[part 1 of 3: packages /AUTOSAR_Dem/ImplementationDataTypes to /AUTOSAR_Dem/SwComponentTypes]
AUTOSAR XML (schema 4-0-3)
package /AUTOSAR_Dem/ImplementationDataTypes
  4 x impl type, all with category=TYPE_REFERENCE, implementation-data-type=uint8:
    Dem_OperationCycleIdType: compu {0=DEM_OPCYC_POWER, 1=DEM_OPCYC_IGN}, range raw 0..1
    Dem_IndicatorIdType: range raw 0
    Dem_RatioIdType: range raw 0
    Dem_EnableConditionType: compu {0=DemConf_DemEnableCondition_CONDITION_Voltage_Normal, 1=DemConf_DemEnableCondition_CONDITION_PowerON_3000ms, 2=DemConf_DemEnableCondition_CONDITION_Voltage_InRange, 3=DemConf_DemEnableCondition_CONDITION_NO_BUSOFF_PublicCAN, 4=DemConf_DemEnableCondition_CONDITION_NO_BUSOFF_PrivateCAN, 5=DemConf_DemEnableCondition_CONDITION_BcmPwrStsFbON, 6=DemConf_DemEnableCondition_CONDITION_EspVehSpd}
package /AUTOSAR_Dem/SwComponentTypes
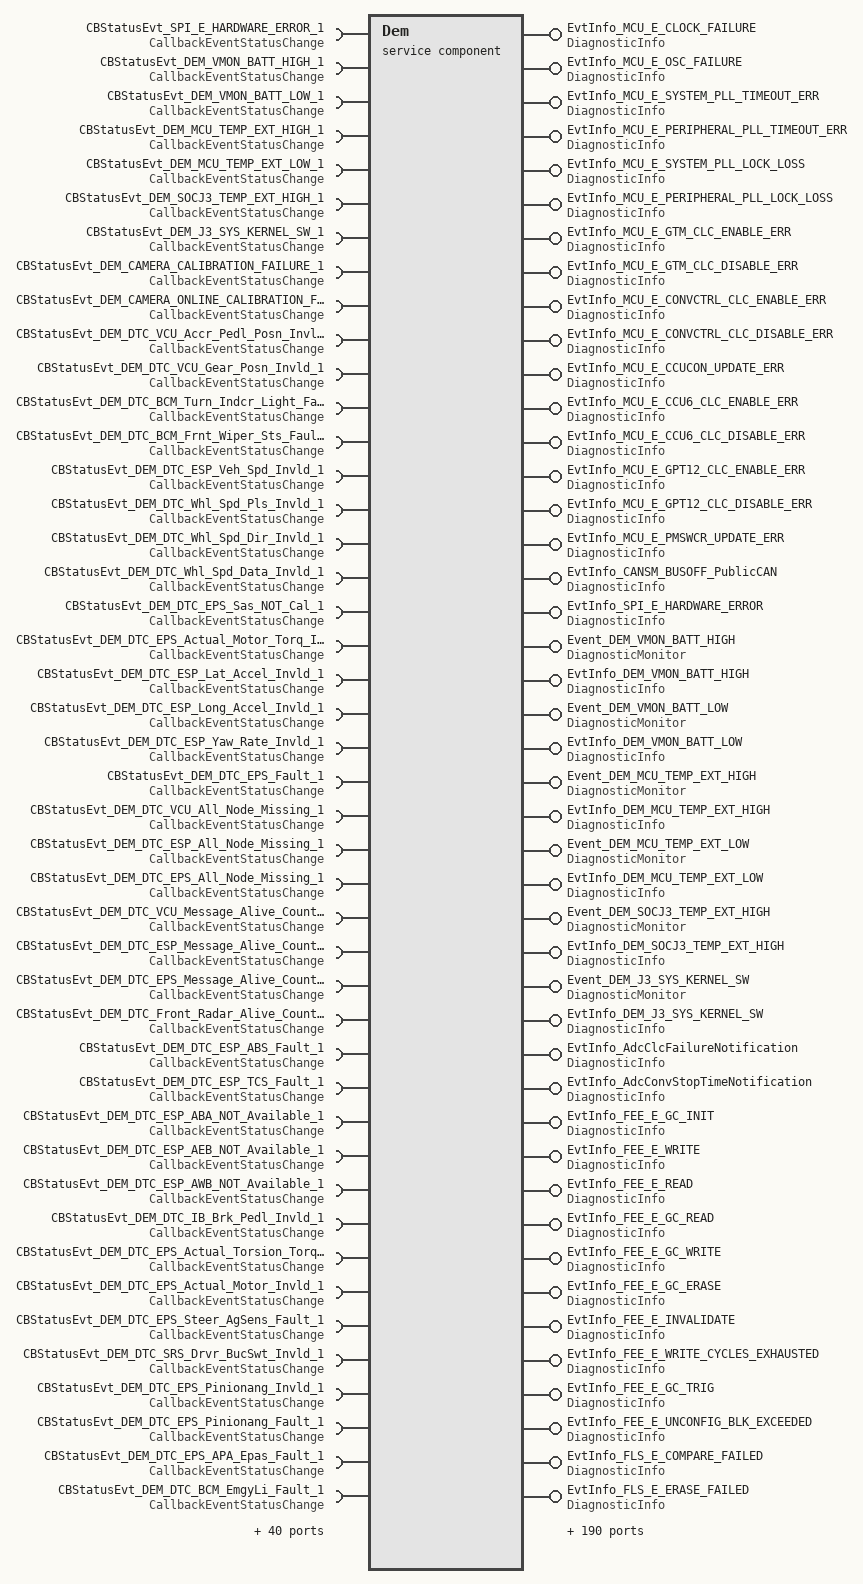
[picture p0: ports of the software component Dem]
  service sw component type Dem
    18 x provide port, all with provided-interface=DiagnosticInfo:
      EvtInfo_MCU_E_CLOCK_FAILURE
        provided-com-specs:
          operation=GetEventStatus, queue-length=1
          operation=GetEventFailed, queue-length=1
          operation=GetEventTested, queue-length=1
          operation=GetDTCOfEvent, queue-length=1
          operation=GetFaultDetectionCounter, queue-length=1
          operation=GetEventFreezeFrameData, queue-length=1
          operation=GetEventExtendedDataRecord, queue-length=1
      EvtInfo_MCU_E_OSC_FAILURE
        provided-com-specs:
          operation=GetEventStatus, queue-length=1
          operation=GetEventFailed, queue-length=1
          operation=GetEventTested, queue-length=1
          operation=GetDTCOfEvent, queue-length=1
          operation=GetFaultDetectionCounter, queue-length=1
          operation=GetEventFreezeFrameData, queue-length=1
          operation=GetEventExtendedDataRecord, queue-length=1
      EvtInfo_MCU_E_SYSTEM_PLL_TIMEOUT_ERR
        provided-com-specs:
          operation=GetEventStatus, queue-length=1
          operation=GetEventFailed, queue-length=1
          operation=GetEventTested, queue-length=1
          operation=GetDTCOfEvent, queue-length=1
          operation=GetFaultDetectionCounter, queue-length=1
          operation=GetEventFreezeFrameData, queue-length=1
          operation=GetEventExtendedDataRecord, queue-length=1
      EvtInfo_MCU_E_PERIPHERAL_PLL_TIMEOUT_ERR
        provided-com-specs:
          operation=GetEventStatus, queue-length=1
          operation=GetEventFailed, queue-length=1
          operation=GetEventTested, queue-length=1
          operation=GetDTCOfEvent, queue-length=1
          operation=GetFaultDetectionCounter, queue-length=1
          operation=GetEventFreezeFrameData, queue-length=1
          operation=GetEventExtendedDataRecord, queue-length=1
      EvtInfo_MCU_E_SYSTEM_PLL_LOCK_LOSS
        provided-com-specs:
          operation=GetEventStatus, queue-length=1
          operation=GetEventFailed, queue-length=1
          operation=GetEventTested, queue-length=1
          operation=GetDTCOfEvent, queue-length=1
          operation=GetFaultDetectionCounter, queue-length=1
          operation=GetEventFreezeFrameData, queue-length=1
          operation=GetEventExtendedDataRecord, queue-length=1
      EvtInfo_MCU_E_PERIPHERAL_PLL_LOCK_LOSS
        provided-com-specs:
          operation=GetEventStatus, queue-length=1
          operation=GetEventFailed, queue-length=1
          operation=GetEventTested, queue-length=1
          operation=GetDTCOfEvent, queue-length=1
          operation=GetFaultDetectionCounter, queue-length=1
          operation=GetEventFreezeFrameData, queue-length=1
          operation=GetEventExtendedDataRecord, queue-length=1
      EvtInfo_MCU_E_GTM_CLC_ENABLE_ERR
        provided-com-specs:
          operation=GetEventStatus, queue-length=1
          operation=GetEventFailed, queue-length=1
          operation=GetEventTested, queue-length=1
          operation=GetDTCOfEvent, queue-length=1
          operation=GetFaultDetectionCounter, queue-length=1
          operation=GetEventFreezeFrameData, queue-length=1
          operation=GetEventExtendedDataRecord, queue-length=1
      EvtInfo_MCU_E_GTM_CLC_DISABLE_ERR
        provided-com-specs:
          operation=GetEventStatus, queue-length=1
          operation=GetEventFailed, queue-length=1
          operation=GetEventTested, queue-length=1
          operation=GetDTCOfEvent, queue-length=1
          operation=GetFaultDetectionCounter, queue-length=1
          operation=GetEventFreezeFrameData, queue-length=1
          operation=GetEventExtendedDataRecord, queue-length=1
      EvtInfo_MCU_E_CONVCTRL_CLC_ENABLE_ERR
        provided-com-specs:
          operation=GetEventStatus, queue-length=1
          operation=GetEventFailed, queue-length=1
          operation=GetEventTested, queue-length=1
          operation=GetDTCOfEvent, queue-length=1
          operation=GetFaultDetectionCounter, queue-length=1
          operation=GetEventFreezeFrameData, queue-length=1
          operation=GetEventExtendedDataRecord, queue-length=1
      EvtInfo_MCU_E_CONVCTRL_CLC_DISABLE_ERR
        provided-com-specs:
          operation=GetEventStatus, queue-length=1
          operation=GetEventFailed, queue-length=1
          operation=GetEventTested, queue-length=1
          operation=GetDTCOfEvent, queue-length=1
          operation=GetFaultDetectionCounter, queue-length=1
          operation=GetEventFreezeFrameData, queue-length=1
          operation=GetEventExtendedDataRecord, queue-length=1
      EvtInfo_MCU_E_CCUCON_UPDATE_ERR
        provided-com-specs:
          operation=GetEventStatus, queue-length=1
          operation=GetEventFailed, queue-length=1
          operation=GetEventTested, queue-length=1
          operation=GetDTCOfEvent, queue-length=1
          operation=GetFaultDetectionCounter, queue-length=1
          operation=GetEventFreezeFrameData, queue-length=1
          operation=GetEventExtendedDataRecord, queue-length=1
      EvtInfo_MCU_E_CCU6_CLC_ENABLE_ERR
        provided-com-specs:
          operation=GetEventStatus, queue-length=1
          operation=GetEventFailed, queue-length=1
          operation=GetEventTested, queue-length=1
          operation=GetDTCOfEvent, queue-length=1
          operation=GetFaultDetectionCounter, queue-length=1
          operation=GetEventFreezeFrameData, queue-length=1
          operation=GetEventExtendedDataRecord, queue-length=1
      EvtInfo_MCU_E_CCU6_CLC_DISABLE_ERR
        provided-com-specs:
          operation=GetEventStatus, queue-length=1
          operation=GetEventFailed, queue-length=1
          operation=GetEventTested, queue-length=1
          operation=GetDTCOfEvent, queue-length=1
          operation=GetFaultDetectionCounter, queue-length=1
          operation=GetEventFreezeFrameData, queue-length=1
          operation=GetEventExtendedDataRecord, queue-length=1
      EvtInfo_MCU_E_GPT12_CLC_ENABLE_ERR
        provided-com-specs:
          operation=GetEventStatus, queue-length=1
          operation=GetEventFailed, queue-length=1
          operation=GetEventTested, queue-length=1
          operation=GetDTCOfEvent, queue-length=1
          operation=GetFaultDetectionCounter, queue-length=1
          operation=GetEventFreezeFrameData, queue-length=1
          operation=GetEventExtendedDataRecord, queue-length=1
      EvtInfo_MCU_E_GPT12_CLC_DISABLE_ERR
        provided-com-specs:
          operation=GetEventStatus, queue-length=1
          operation=GetEventFailed, queue-length=1
          operation=GetEventTested, queue-length=1
          operation=GetDTCOfEvent, queue-length=1
          operation=GetFaultDetectionCounter, queue-length=1
          operation=GetEventFreezeFrameData, queue-length=1
          operation=GetEventExtendedDataRecord, queue-length=1
      EvtInfo_MCU_E_PMSWCR_UPDATE_ERR
        provided-com-specs:
          operation=GetEventStatus, queue-length=1
          operation=GetEventFailed, queue-length=1
          operation=GetEventTested, queue-length=1
          operation=GetDTCOfEvent, queue-length=1
          operation=GetFaultDetectionCounter, queue-length=1
          operation=GetEventFreezeFrameData, queue-length=1
          operation=GetEventExtendedDataRecord, queue-length=1
      EvtInfo_CANSM_BUSOFF_PublicCAN
        provided-com-specs:
          operation=GetEventStatus, queue-length=1
          operation=GetEventFailed, queue-length=1
          operation=GetEventTested, queue-length=1
          operation=GetDTCOfEvent, queue-length=1
          operation=GetFaultDetectionCounter, queue-length=1
          operation=GetEventFreezeFrameData, queue-length=1
          operation=GetEventExtendedDataRecord, queue-length=1
      EvtInfo_SPI_E_HARDWARE_ERROR
        provided-com-specs:
          operation=GetEventStatus, queue-length=1
          operation=GetEventFailed, queue-length=1
          operation=GetEventTested, queue-length=1
          operation=GetDTCOfEvent, queue-length=1
          operation=GetFaultDetectionCounter, queue-length=1
          operation=GetEventFreezeFrameData, queue-length=1
          operation=GetEventExtendedDataRecord, queue-length=1
    require port CBStatusEvt_SPI_E_HARDWARE_ERROR_1: required-interface=CallbackEventStatusChange
    provide port Event_DEM_VMON_BATT_HIGH: provided-interface=DiagnosticMonitor
      provided-com-specs:
        operation=SetEventStatus, queue-length=1
        operation=ResetEventStatus, queue-length=1
        operation=PrestoreFreezeFrame, queue-length=1
        operation=ClearPrestoredFreezeFrame, queue-length=1
        operation=ResetEventDebounceStatus, queue-length=1
    provide port EvtInfo_DEM_VMON_BATT_HIGH: provided-interface=DiagnosticInfo
      provided-com-specs:
        operation=GetEventStatus, queue-length=1
        operation=GetEventFailed, queue-length=1
        operation=GetEventTested, queue-length=1
        operation=GetDTCOfEvent, queue-length=1
        operation=GetFaultDetectionCounter, queue-length=1
        operation=GetEventFreezeFrameData, queue-length=1
        operation=GetEventExtendedDataRecord, queue-length=1
    require port CBStatusEvt_DEM_VMON_BATT_HIGH_1: required-interface=CallbackEventStatusChange
    provide port Event_DEM_VMON_BATT_LOW: provided-interface=DiagnosticMonitor
      provided-com-specs:
        operation=SetEventStatus, queue-length=1
        operation=ResetEventStatus, queue-length=1
        operation=PrestoreFreezeFrame, queue-length=1
        operation=ClearPrestoredFreezeFrame, queue-length=1
        operation=ResetEventDebounceStatus, queue-length=1
    provide port EvtInfo_DEM_VMON_BATT_LOW: provided-interface=DiagnosticInfo
      provided-com-specs:
        operation=GetEventStatus, queue-length=1
        operation=GetEventFailed, queue-length=1
        operation=GetEventTested, queue-length=1
        operation=GetDTCOfEvent, queue-length=1
        operation=GetFaultDetectionCounter, queue-length=1
        operation=GetEventFreezeFrameData, queue-length=1
        operation=GetEventExtendedDataRecord, queue-length=1
    require port CBStatusEvt_DEM_VMON_BATT_LOW_1: required-interface=CallbackEventStatusChange
    provide port Event_DEM_MCU_TEMP_EXT_HIGH: provided-interface=DiagnosticMonitor
      provided-com-specs:
        operation=SetEventStatus, queue-length=1
        operation=ResetEventStatus, queue-length=1
        operation=PrestoreFreezeFrame, queue-length=1
        operation=ClearPrestoredFreezeFrame, queue-length=1
        operation=ResetEventDebounceStatus, queue-length=1
    provide port EvtInfo_DEM_MCU_TEMP_EXT_HIGH: provided-interface=DiagnosticInfo
      provided-com-specs:
        operation=GetEventStatus, queue-length=1
        operation=GetEventFailed, queue-length=1
        operation=GetEventTested, queue-length=1
        operation=GetDTCOfEvent, queue-length=1
        operation=GetFaultDetectionCounter, queue-length=1
        operation=GetEventFreezeFrameData, queue-length=1
        operation=GetEventExtendedDataRecord, queue-length=1
    require port CBStatusEvt_DEM_MCU_TEMP_EXT_HIGH_1: required-interface=CallbackEventStatusChange
    provide port Event_DEM_MCU_TEMP_EXT_LOW: provided-interface=DiagnosticMonitor
      provided-com-specs:
        operation=SetEventStatus, queue-length=1
        operation=ResetEventStatus, queue-length=1
        operation=PrestoreFreezeFrame, queue-length=1
        operation=ClearPrestoredFreezeFrame, queue-length=1
        operation=ResetEventDebounceStatus, queue-length=1
    provide port EvtInfo_DEM_MCU_TEMP_EXT_LOW: provided-interface=DiagnosticInfo
      provided-com-specs:
        operation=GetEventStatus, queue-length=1
        operation=GetEventFailed, queue-length=1
        operation=GetEventTested, queue-length=1
        operation=GetDTCOfEvent, queue-length=1
        operation=GetFaultDetectionCounter, queue-length=1
        operation=GetEventFreezeFrameData, queue-length=1
        operation=GetEventExtendedDataRecord, queue-length=1
    require port CBStatusEvt_DEM_MCU_TEMP_EXT_LOW_1: required-interface=CallbackEventStatusChange
    provide port Event_DEM_SOCJ3_TEMP_EXT_HIGH: provided-interface=DiagnosticMonitor
      provided-com-specs:
        operation=SetEventStatus, queue-length=1
        operation=ResetEventStatus, queue-length=1
        operation=PrestoreFreezeFrame, queue-length=1
        operation=ClearPrestoredFreezeFrame, queue-length=1
        operation=ResetEventDebounceStatus, queue-length=1
    provide port EvtInfo_DEM_SOCJ3_TEMP_EXT_HIGH: provided-interface=DiagnosticInfo
      provided-com-specs:
        operation=GetEventStatus, queue-length=1
        operation=GetEventFailed, queue-length=1
        operation=GetEventTested, queue-length=1
        operation=GetDTCOfEvent, queue-length=1
        operation=GetFaultDetectionCounter, queue-length=1
        operation=GetEventFreezeFrameData, queue-length=1
        operation=GetEventExtendedDataRecord, queue-length=1
    require port CBStatusEvt_DEM_SOCJ3_TEMP_EXT_HIGH_1: required-interface=CallbackEventStatusChange
    provide port Event_DEM_J3_SYS_KERNEL_SW: provided-interface=DiagnosticMonitor
      provided-com-specs:
        operation=SetEventStatus, queue-length=1
        operation=ResetEventStatus, queue-length=1
        operation=PrestoreFreezeFrame, queue-length=1
        operation=ClearPrestoredFreezeFrame, queue-length=1
        operation=ResetEventDebounceStatus, queue-length=1
    provide port EvtInfo_DEM_J3_SYS_KERNEL_SW: provided-interface=DiagnosticInfo
      provided-com-specs:
        operation=GetEventStatus, queue-length=1
        operation=GetEventFailed, queue-length=1
        operation=GetEventTested, queue-length=1
        operation=GetDTCOfEvent, queue-length=1
        operation=GetFaultDetectionCounter, queue-length=1
        operation=GetEventFreezeFrameData, queue-length=1
        operation=GetEventExtendedDataRecord, queue-length=1
    require port CBStatusEvt_DEM_J3_SYS_KERNEL_SW_1: required-interface=CallbackEventStatusChange
    19 x provide port:
      EvtInfo_AdcClcFailureNotification: provided-interface=DiagnosticInfo
        provided-com-specs:
          operation=GetEventStatus, queue-length=1
          operation=GetEventFailed, queue-length=1
          operation=GetEventTested, queue-length=1
          operation=GetDTCOfEvent, queue-length=1
          operation=GetFaultDetectionCounter, queue-length=1
          operation=GetEventFreezeFrameData, queue-length=1
          operation=GetEventExtendedDataRecord, queue-length=1
      EvtInfo_AdcConvStopTimeNotification: provided-interface=DiagnosticInfo
        provided-com-specs:
          operation=GetEventStatus, queue-length=1
          operation=GetEventFailed, queue-length=1
          operation=GetEventTested, queue-length=1
          operation=GetDTCOfEvent, queue-length=1
          operation=GetFaultDetectionCounter, queue-length=1
          operation=GetEventFreezeFrameData, queue-length=1
          operation=GetEventExtendedDataRecord, queue-length=1
      EvtInfo_FEE_E_GC_INIT: provided-interface=DiagnosticInfo
        provided-com-specs:
          operation=GetEventStatus, queue-length=1
          operation=GetEventFailed, queue-length=1
          operation=GetEventTested, queue-length=1
          operation=GetDTCOfEvent, queue-length=1
          operation=GetFaultDetectionCounter, queue-length=1
          operation=GetEventFreezeFrameData, queue-length=1
          operation=GetEventExtendedDataRecord, queue-length=1
      EvtInfo_FEE_E_WRITE: provided-interface=DiagnosticInfo
        provided-com-specs:
          operation=GetEventStatus, queue-length=1
          operation=GetEventFailed, queue-length=1
          operation=GetEventTested, queue-length=1
          operation=GetDTCOfEvent, queue-length=1
          operation=GetFaultDetectionCounter, queue-length=1
          operation=GetEventFreezeFrameData, queue-length=1
          operation=GetEventExtendedDataRecord, queue-length=1
      EvtInfo_FEE_E_READ: provided-interface=DiagnosticInfo
        provided-com-specs:
          operation=GetEventStatus, queue-length=1
          operation=GetEventFailed, queue-length=1
          operation=GetEventTested, queue-length=1
          operation=GetDTCOfEvent, queue-length=1
          operation=GetFaultDetectionCounter, queue-length=1
          operation=GetEventFreezeFrameData, queue-length=1
          operation=GetEventExtendedDataRecord, queue-length=1
      EvtInfo_FEE_E_GC_READ: provided-interface=DiagnosticInfo
        provided-com-specs:
          operation=GetEventStatus, queue-length=1
          operation=GetEventFailed, queue-length=1
          operation=GetEventTested, queue-length=1
          operation=GetDTCOfEvent, queue-length=1
          operation=GetFaultDetectionCounter, queue-length=1
          operation=GetEventFreezeFrameData, queue-length=1
          operation=GetEventExtendedDataRecord, queue-length=1
      EvtInfo_FEE_E_GC_WRITE: provided-interface=DiagnosticInfo
        provided-com-specs:
          operation=GetEventStatus, queue-length=1
          operation=GetEventFailed, queue-length=1
          operation=GetEventTested, queue-length=1
          operation=GetDTCOfEvent, queue-length=1
          operation=GetFaultDetectionCounter, queue-length=1
          operation=GetEventFreezeFrameData, queue-length=1
          operation=GetEventExtendedDataRecord, queue-length=1
      EvtInfo_FEE_E_GC_ERASE: provided-interface=DiagnosticInfo
        provided-com-specs:
          operation=GetEventStatus, queue-length=1
          operation=GetEventFailed, queue-length=1
          operation=GetEventTested, queue-length=1
          operation=GetDTCOfEvent, queue-length=1
          operation=GetFaultDetectionCounter, queue-length=1
          operation=GetEventFreezeFrameData, queue-length=1
          operation=GetEventExtendedDataRecord, queue-length=1
      EvtInfo_FEE_E_INVALIDATE: provided-interface=DiagnosticInfo
        provided-com-specs:
          operation=GetEventStatus, queue-length=1
          operation=GetEventFailed, queue-length=1
          operation=GetEventTested, queue-length=1
          operation=GetDTCOfEvent, queue-length=1
          operation=GetFaultDetectionCounter, queue-length=1
          operation=GetEventFreezeFrameData, queue-length=1
          operation=GetEventExtendedDataRecord, queue-length=1
      EvtInfo_FEE_E_WRITE_CYCLES_EXHAUSTED: provided-interface=DiagnosticInfo
        provided-com-specs:
          operation=GetEventStatus, queue-length=1
          operation=GetEventFailed, queue-length=1
          operation=GetEventTested, queue-length=1
          operation=GetDTCOfEvent, queue-length=1
          operation=GetFaultDetectionCounter, queue-length=1
          operation=GetEventFreezeFrameData, queue-length=1
          operation=GetEventExtendedDataRecord, queue-length=1
      EvtInfo_FEE_E_GC_TRIG: provided-interface=DiagnosticInfo
        provided-com-specs:
          operation=GetEventStatus, queue-length=1
          operation=GetEventFailed, queue-length=1
          operation=GetEventTested, queue-length=1
          operation=GetDTCOfEvent, queue-length=1
          operation=GetFaultDetectionCounter, queue-length=1
          operation=GetEventFreezeFrameData, queue-length=1
          operation=GetEventExtendedDataRecord, queue-length=1
      EvtInfo_FEE_E_UNCONFIG_BLK_EXCEEDED: provided-interface=DiagnosticInfo
        provided-com-specs:
          operation=GetEventStatus, queue-length=1
          operation=GetEventFailed, queue-length=1
          operation=GetEventTested, queue-length=1
          operation=GetDTCOfEvent, queue-length=1
          operation=GetFaultDetectionCounter, queue-length=1
          operation=GetEventFreezeFrameData, queue-length=1
          operation=GetEventExtendedDataRecord, queue-length=1
      EvtInfo_FLS_E_COMPARE_FAILED: provided-interface=DiagnosticInfo
        provided-com-specs:
          operation=GetEventStatus, queue-length=1
          operation=GetEventFailed, queue-length=1
          operation=GetEventTested, queue-length=1
          operation=GetDTCOfEvent, queue-length=1
          operation=GetFaultDetectionCounter, queue-length=1
          operation=GetEventFreezeFrameData, queue-length=1
          operation=GetEventExtendedDataRecord, queue-length=1
      EvtInfo_FLS_E_ERASE_FAILED: provided-interface=DiagnosticInfo
        provided-com-specs:
          operation=GetEventStatus, queue-length=1
          operation=GetEventFailed, queue-length=1
          operation=GetEventTested, queue-length=1
          operation=GetDTCOfEvent, queue-length=1
          operation=GetFaultDetectionCounter, queue-length=1
          operation=GetEventFreezeFrameData, queue-length=1
          operation=GetEventExtendedDataRecord, queue-length=1
      EvtInfo_FLS_E_READ_FAILED: provided-interface=DiagnosticInfo
        provided-com-specs:
          operation=GetEventStatus, queue-length=1
          operation=GetEventFailed, queue-length=1
          operation=GetEventTested, queue-length=1
          operation=GetDTCOfEvent, queue-length=1
          operation=GetFaultDetectionCounter, queue-length=1
          operation=GetEventFreezeFrameData, queue-length=1
          operation=GetEventExtendedDataRecord, queue-length=1
      EvtInfo_FLS_E_UNEXPECTED_FLASH_ID: provided-interface=DiagnosticInfo
        provided-com-specs:
          operation=GetEventStatus, queue-length=1
          operation=GetEventFailed, queue-length=1
          operation=GetEventTested, queue-length=1
          operation=GetDTCOfEvent, queue-length=1
          operation=GetFaultDetectionCounter, queue-length=1
          operation=GetEventFreezeFrameData, queue-length=1
          operation=GetEventExtendedDataRecord, queue-length=1
      EvtInfo_FLS_E_WRITE_FAILED: provided-interface=DiagnosticInfo
        provided-com-specs:
          operation=GetEventStatus, queue-length=1
          operation=GetEventFailed, queue-length=1
          operation=GetEventTested, queue-length=1
          operation=GetDTCOfEvent, queue-length=1
          operation=GetFaultDetectionCounter, queue-length=1
          operation=GetEventFreezeFrameData, queue-length=1
          operation=GetEventExtendedDataRecord, queue-length=1
      Event_DEM_CAMERA_CALIBRATION_FAILURE: provided-interface=DiagnosticMonitor
        provided-com-specs:
          operation=SetEventStatus, queue-length=1
          operation=ResetEventStatus, queue-length=1
          operation=PrestoreFreezeFrame, queue-length=1
          operation=ClearPrestoredFreezeFrame, queue-length=1
          operation=ResetEventDebounceStatus, queue-length=1
      EvtInfo_DEM_CAMERA_CALIBRATION_FAILURE: provided-interface=DiagnosticInfo
        provided-com-specs:
          operation=GetEventStatus, queue-length=1
          operation=GetEventFailed, queue-length=1
          operation=GetEventTested, queue-length=1
          operation=GetDTCOfEvent, queue-length=1
          operation=GetFaultDetectionCounter, queue-length=1
          operation=GetEventFreezeFrameData, queue-length=1
          operation=GetEventExtendedDataRecord, queue-length=1
    require port CBStatusEvt_DEM_CAMERA_CALIBRATION_FAILURE_1: required-interface=CallbackEventStatusChange
    provide port Event_DEM_CAMERA_ONLINE_CALIBRATION_FAILURE: provided-interface=DiagnosticMonitor
      provided-com-specs:
        operation=SetEventStatus, queue-length=1
        operation=ResetEventStatus, queue-length=1
        operation=PrestoreFreezeFrame, queue-length=1
        operation=ClearPrestoredFreezeFrame, queue-length=1
        operation=ResetEventDebounceStatus, queue-length=1
    provide port EvtInfo_DEM_CAMERA_ONLINE_CALIBRATION_FAILURE: provided-interface=DiagnosticInfo
      provided-com-specs:
        operation=GetEventStatus, queue-length=1
        operation=GetEventFailed, queue-length=1
        operation=GetEventTested, queue-length=1
        operation=GetDTCOfEvent, queue-length=1
        operation=GetFaultDetectionCounter, queue-length=1
        operation=GetEventFreezeFrameData, queue-length=1
        operation=GetEventExtendedDataRecord, queue-length=1
    require port CBStatusEvt_DEM_CAMERA_ONLINE_CALIBRATION_FAILURE_1: required-interface=CallbackEventStatusChange
    provide port EvtInfo_CANSM_BUSOFF_PrivateCAN: provided-interface=DiagnosticInfo
      provided-com-specs:
        operation=GetEventStatus, queue-length=1
        operation=GetEventFailed, queue-length=1
        operation=GetEventTested, queue-length=1
        operation=GetDTCOfEvent, queue-length=1
        operation=GetFaultDetectionCounter, queue-length=1
        operation=GetEventFreezeFrameData, queue-length=1
        operation=GetEventExtendedDataRecord, queue-length=1
    provide port Event_DEM_DTC_VCU_Accr_Pedl_Posn_Invld: provided-interface=DiagnosticMonitor
      provided-com-specs:
        operation=SetEventStatus, queue-length=1
        operation=ResetEventStatus, queue-length=1
        operation=PrestoreFreezeFrame, queue-length=1
        operation=ClearPrestoredFreezeFrame, queue-length=1
        operation=ResetEventDebounceStatus, queue-length=1
    provide port EvtInfo_DEM_DTC_VCU_Accr_Pedl_Posn_Invld: provided-interface=DiagnosticInfo
      provided-com-specs:
        operation=GetEventStatus, queue-length=1
        operation=GetEventFailed, queue-length=1
        operation=GetEventTested, queue-length=1
        operation=GetDTCOfEvent, queue-length=1
        operation=GetFaultDetectionCounter, queue-length=1
        operation=GetEventFreezeFrameData, queue-length=1
        operation=GetEventExtendedDataRecord, queue-length=1
    require port CBStatusEvt_DEM_DTC_VCU_Accr_Pedl_Posn_Invld_1: required-interface=CallbackEventStatusChange
    provide port Event_DEM_DTC_VCU_Gear_Posn_Invld: provided-interface=DiagnosticMonitor
      provided-com-specs:
        operation=SetEventStatus, queue-length=1
        operation=ResetEventStatus, queue-length=1
        operation=PrestoreFreezeFrame, queue-length=1
        operation=ClearPrestoredFreezeFrame, queue-length=1
        operation=ResetEventDebounceStatus, queue-length=1
    provide port EvtInfo_DEM_DTC_VCU_Gear_Posn_Invld: provided-interface=DiagnosticInfo
      provided-com-specs:
        operation=GetEventStatus, queue-length=1
        operation=GetEventFailed, queue-length=1
        operation=GetEventTested, queue-length=1
        operation=GetDTCOfEvent, queue-length=1
        operation=GetFaultDetectionCounter, queue-length=1
        operation=GetEventFreezeFrameData, queue-length=1
        operation=GetEventExtendedDataRecord, queue-length=1
    require port CBStatusEvt_DEM_DTC_VCU_Gear_Posn_Invld_1: required-interface=CallbackEventStatusChange
    provide port Event_DEM_DTC_BCM_Turn_Indcr_Light_Fault: provided-interface=DiagnosticMonitor
      provided-com-specs:
        operation=SetEventStatus, queue-length=1
        operation=ResetEventStatus, queue-length=1
        operation=PrestoreFreezeFrame, queue-length=1
        operation=ClearPrestoredFreezeFrame, queue-length=1
        operation=ResetEventDebounceStatus, queue-length=1
    provide port EvtInfo_DEM_DTC_BCM_Turn_Indcr_Light_Fault: provided-interface=DiagnosticInfo
      provided-com-specs:
        operation=GetEventStatus, queue-length=1
        operation=GetEventFailed, queue-length=1
        operation=GetEventTested, queue-length=1
        operation=GetDTCOfEvent, queue-length=1
        operation=GetFaultDetectionCounter, queue-length=1
        operation=GetEventFreezeFrameData, queue-length=1
        operation=GetEventExtendedDataRecord, queue-length=1
    require port CBStatusEvt_DEM_DTC_BCM_Turn_Indcr_Light_Fault_1: required-interface=CallbackEventStatusChange
    provide port Event_DEM_DTC_BCM_Frnt_Wiper_Sts_Fault: provided-interface=DiagnosticMonitor
      provided-com-specs:
        operation=SetEventStatus, queue-length=1
        operation=ResetEventStatus, queue-length=1
        operation=PrestoreFreezeFrame, queue-length=1
        operation=ClearPrestoredFreezeFrame, queue-length=1
        operation=ResetEventDebounceStatus, queue-length=1
    provide port EvtInfo_DEM_DTC_BCM_Frnt_Wiper_Sts_Fault: provided-interface=DiagnosticInfo
      provided-com-specs:
        operation=GetEventStatus, queue-length=1
        operation=GetEventFailed, queue-length=1
        operation=GetEventTested, queue-length=1
        operation=GetDTCOfEvent, queue-length=1
        operation=GetFaultDetectionCounter, queue-length=1
        operation=GetEventFreezeFrameData, queue-length=1
        operation=GetEventExtendedDataRecord, queue-length=1
    require port CBStatusEvt_DEM_DTC_BCM_Frnt_Wiper_Sts_Fault_1: required-interface=CallbackEventStatusChange
    provide port Event_DEM_DTC_ESP_Veh_Spd_Invld: provided-interface=DiagnosticMonitor
      provided-com-specs:
        operation=SetEventStatus, queue-length=1
        operation=ResetEventStatus, queue-length=1
        operation=PrestoreFreezeFrame, queue-length=1
        operation=ClearPrestoredFreezeFrame, queue-length=1
        operation=ResetEventDebounceStatus, queue-length=1
    provide port EvtInfo_DEM_DTC_ESP_Veh_Spd_Invld: provided-interface=DiagnosticInfo
      provided-com-specs:
        operation=GetEventStatus, queue-length=1
        operation=GetEventFailed, queue-length=1
        operation=GetEventTested, queue-length=1
        operation=GetDTCOfEvent, queue-length=1
        operation=GetFaultDetectionCounter, queue-length=1
        operation=GetEventFreezeFrameData, queue-length=1
        operation=GetEventExtendedDataRecord, queue-length=1
    require port CBStatusEvt_DEM_DTC_ESP_Veh_Spd_Invld_1: required-interface=CallbackEventStatusChange
    provide port Event_DEM_DTC_Whl_Spd_Pls_Invld: provided-interface=DiagnosticMonitor
      provided-com-specs:
        operation=SetEventStatus, queue-length=1
        operation=ResetEventStatus, queue-length=1
        operation=PrestoreFreezeFrame, queue-length=1
        operation=ClearPrestoredFreezeFrame, queue-length=1
        operation=ResetEventDebounceStatus, queue-length=1
    provide port EvtInfo_DEM_DTC_Whl_Spd_Pls_Invld: provided-interface=DiagnosticInfo
      provided-com-specs:
        operation=GetEventStatus, queue-length=1
        operation=GetEventFailed, queue-length=1
        operation=GetEventTested, queue-length=1
        operation=GetDTCOfEvent, queue-length=1
        operation=GetFaultDetectionCounter, queue-length=1
        operation=GetEventFreezeFrameData, queue-length=1
        operation=GetEventExtendedDataRecord, queue-length=1
    require port CBStatusEvt_DEM_DTC_Whl_Spd_Pls_Invld_1: required-interface=CallbackEventStatusChange
    provide port Event_DEM_DTC_Whl_Spd_Dir_Invld: provided-interface=DiagnosticMonitor
      provided-com-specs:
        operation=SetEventStatus, queue-length=1
        operation=ResetEventStatus, queue-length=1
        operation=PrestoreFreezeFrame, queue-length=1
        operation=ClearPrestoredFreezeFrame, queue-length=1
        operation=ResetEventDebounceStatus, queue-length=1
    provide port EvtInfo_DEM_DTC_Whl_Spd_Dir_Invld: provided-interface=DiagnosticInfo
      provided-com-specs:
        operation=GetEventStatus, queue-length=1
        operation=GetEventFailed, queue-length=1
        operation=GetEventTested, queue-length=1
        operation=GetDTCOfEvent, queue-length=1
        operation=GetFaultDetectionCounter, queue-length=1
        operation=GetEventFreezeFrameData, queue-length=1
        operation=GetEventExtendedDataRecord, queue-length=1
    require port CBStatusEvt_DEM_DTC_Whl_Spd_Dir_Invld_1: required-interface=CallbackEventStatusChange
    provide port Event_DEM_DTC_Whl_Spd_Data_Invld: provided-interface=DiagnosticMonitor
      provided-com-specs:
        operation=SetEventStatus, queue-length=1
        operation=ResetEventStatus, queue-length=1
        operation=PrestoreFreezeFrame, queue-length=1
        operation=ClearPrestoredFreezeFrame, queue-length=1
        operation=ResetEventDebounceStatus, queue-length=1
    provide port EvtInfo_DEM_DTC_Whl_Spd_Data_Invld: provided-interface=DiagnosticInfo
      provided-com-specs:
        operation=GetEventStatus, queue-length=1
        operation=GetEventFailed, queue-length=1
        operation=GetEventTested, queue-length=1
        operation=GetDTCOfEvent, queue-length=1
        operation=GetFaultDetectionCounter, queue-length=1
        operation=GetEventFreezeFrameData, queue-length=1
        operation=GetEventExtendedDataRecord, queue-length=1
    require port CBStatusEvt_DEM_DTC_Whl_Spd_Data_Invld_1: required-interface=CallbackEventStatusChange
    provide port Event_DEM_DTC_EPS_Sas_NOT_Cal: provided-interface=DiagnosticMonitor
      provided-com-specs:
        operation=SetEventStatus, queue-length=1
        operation=ResetEventStatus, queue-length=1
        operation=PrestoreFreezeFrame, queue-length=1
        operation=ClearPrestoredFreezeFrame, queue-length=1
        operation=ResetEventDebounceStatus, queue-length=1
    provide port EvtInfo_DEM_DTC_EPS_Sas_NOT_Cal: provided-interface=DiagnosticInfo
      provided-com-specs:
        operation=GetEventStatus, queue-length=1
        operation=GetEventFailed, queue-length=1
        operation=GetEventTested, queue-length=1
        operation=GetDTCOfEvent, queue-length=1
        operation=GetFaultDetectionCounter, queue-length=1
        operation=GetEventFreezeFrameData, queue-length=1
        operation=GetEventExtendedDataRecord, queue-length=1
    require port CBStatusEvt_DEM_DTC_EPS_Sas_NOT_Cal_1: required-interface=CallbackEventStatusChange
    provide port Event_DEM_DTC_EPS_Actual_Motor_Torq_Invld: provided-interface=DiagnosticMonitor
      provided-com-specs:
        operation=SetEventStatus, queue-length=1
        operation=ResetEventStatus, queue-length=1
        operation=PrestoreFreezeFrame, queue-length=1
        operation=ClearPrestoredFreezeFrame, queue-length=1
        operation=ResetEventDebounceStatus, queue-length=1
    provide port EvtInfo_DEM_DTC_EPS_Actual_Motor_Torq_Invld: provided-interface=DiagnosticInfo
      provided-com-specs:
        operation=GetEventStatus, queue-length=1
        operation=GetEventFailed, queue-length=1
        operation=GetEventTested, queue-length=1
        operation=GetDTCOfEvent, queue-length=1
        operation=GetFaultDetectionCounter, queue-length=1
        operation=GetEventFreezeFrameData, queue-length=1
        operation=GetEventExtendedDataRecord, queue-length=1
    require port CBStatusEvt_DEM_DTC_EPS_Actual_Motor_Torq_Invld_1: required-interface=CallbackEventStatusChange
    provide port Event_DEM_DTC_ESP_Lat_Accel_Invld: provided-interface=DiagnosticMonitor
      provided-com-specs:
        operation=SetEventStatus, queue-length=1
        operation=ResetEventStatus, queue-length=1
        operation=PrestoreFreezeFrame, queue-length=1
        operation=ClearPrestoredFreezeFrame, queue-length=1
        operation=ResetEventDebounceStatus, queue-length=1
    provide port EvtInfo_DEM_DTC_ESP_Lat_Accel_Invld: provided-interface=DiagnosticInfo
      provided-com-specs:
        operation=GetEventStatus, queue-length=1
        operation=GetEventFailed, queue-length=1
        operation=GetEventTested, queue-length=1
        operation=GetDTCOfEvent, queue-length=1
        operation=GetFaultDetectionCounter, queue-length=1
        operation=GetEventFreezeFrameData, queue-length=1
        operation=GetEventExtendedDataRecord, queue-length=1
    require port CBStatusEvt_DEM_DTC_ESP_Lat_Accel_Invld_1: required-interface=CallbackEventStatusChange
    provide port Event_DEM_DTC_ESP_Long_Accel_Invld: provided-interface=DiagnosticMonitor
      provided-com-specs:
        operation=SetEventStatus, queue-length=1
        operation=ResetEventStatus, queue-length=1
        operation=PrestoreFreezeFrame, queue-length=1
        operation=ClearPrestoredFreezeFrame, queue-length=1
        operation=ResetEventDebounceStatus, queue-length=1
    provide port EvtInfo_DEM_DTC_ESP_Long_Accel_Invld: provided-interface=DiagnosticInfo
      provided-com-specs:
        operation=GetEventStatus, queue-length=1
        operation=GetEventFailed, queue-length=1
        operation=GetEventTested, queue-length=1
        operation=GetDTCOfEvent, queue-length=1
        operation=GetFaultDetectionCounter, queue-length=1
        operation=GetEventFreezeFrameData, queue-length=1
        operation=GetEventExtendedDataRecord, queue-length=1
    require port CBStatusEvt_DEM_DTC_ESP_Long_Accel_Invld_1: required-interface=CallbackEventStatusChange
    provide port Event_DEM_DTC_ESP_Yaw_Rate_Invld: provided-interface=DiagnosticMonitor
      provided-com-specs:
        operation=SetEventStatus, queue-length=1
        operation=ResetEventStatus, queue-length=1
        operation=PrestoreFreezeFrame, queue-length=1
        operation=ClearPrestoredFreezeFrame, queue-length=1
        operation=ResetEventDebounceStatus, queue-length=1
    provide port EvtInfo_DEM_DTC_ESP_Yaw_Rate_Invld: provided-interface=DiagnosticInfo
      provided-com-specs:
        operation=GetEventStatus, queue-length=1
        operation=GetEventFailed, queue-length=1
        operation=GetEventTested, queue-length=1
        operation=GetDTCOfEvent, queue-length=1
        operation=GetFaultDetectionCounter, queue-length=1
        operation=GetEventFreezeFrameData, queue-length=1
        operation=GetEventExtendedDataRecord, queue-length=1
    require port CBStatusEvt_DEM_DTC_ESP_Yaw_Rate_Invld_1: required-interface=CallbackEventStatusChange
    provide port Event_DEM_DTC_EPS_Fault: provided-interface=DiagnosticMonitor
      provided-com-specs:
        operation=SetEventStatus, queue-length=1
        operation=ResetEventStatus, queue-length=1
        operation=PrestoreFreezeFrame, queue-length=1
        operation=ClearPrestoredFreezeFrame, queue-length=1
        operation=ResetEventDebounceStatus, queue-length=1
    provide port EvtInfo_DEM_DTC_EPS_Fault: provided-interface=DiagnosticInfo
      provided-com-specs:
        operation=GetEventStatus, queue-length=1
        operation=GetEventFailed, queue-length=1
        operation=GetEventTested, queue-length=1
        operation=GetDTCOfEvent, queue-length=1
        operation=GetFaultDetectionCounter, queue-length=1
        operation=GetEventFreezeFrameData, queue-length=1
        operation=GetEventExtendedDataRecord, queue-length=1
    require port CBStatusEvt_DEM_DTC_EPS_Fault_1: required-interface=CallbackEventStatusChange
    provide port Event_DEM_DTC_VCU_All_Node_Missing: provided-interface=DiagnosticMonitor
      provided-com-specs:
        operation=SetEventStatus, queue-length=1
        operation=ResetEventStatus, queue-length=1
        operation=PrestoreFreezeFrame, queue-length=1
        operation=ClearPrestoredFreezeFrame, queue-length=1
        operation=ResetEventDebounceStatus, queue-length=1
    provide port EvtInfo_DEM_DTC_VCU_All_Node_Missing: provided-interface=DiagnosticInfo
      provided-com-specs:
        operation=GetEventStatus, queue-length=1
        operation=GetEventFailed, queue-length=1
        operation=GetEventTested, queue-length=1
        operation=GetDTCOfEvent, queue-length=1
        operation=GetFaultDetectionCounter, queue-length=1
        operation=GetEventFreezeFrameData, queue-length=1
        operation=GetEventExtendedDataRecord, queue-length=1
    require port CBStatusEvt_DEM_DTC_VCU_All_Node_Missing_1: required-interface=CallbackEventStatusChange
    provide port Event_DEM_DTC_ESP_All_Node_Missing: provided-interface=DiagnosticMonitor
      provided-com-specs:
        operation=SetEventStatus, queue-length=1
        operation=ResetEventStatus, queue-length=1
        operation=PrestoreFreezeFrame, queue-length=1
        operation=ClearPrestoredFreezeFrame, queue-length=1
        operation=ResetEventDebounceStatus, queue-length=1
    provide port EvtInfo_DEM_DTC_ESP_All_Node_Missing: provided-interface=DiagnosticInfo
      provided-com-specs:
        operation=GetEventStatus, queue-length=1
        operation=GetEventFailed, queue-length=1
        operation=GetEventTested, queue-length=1
        operation=GetDTCOfEvent, queue-length=1
        operation=GetFaultDetectionCounter, queue-length=1
        operation=GetEventFreezeFrameData, queue-length=1
        operation=GetEventExtendedDataRecord, queue-length=1
    require port CBStatusEvt_DEM_DTC_ESP_All_Node_Missing_1: required-interface=CallbackEventStatusChange
    provide port Event_DEM_DTC_EPS_All_Node_Missing: provided-interface=DiagnosticMonitor
      provided-com-specs:
        operation=SetEventStatus, queue-length=1
        operation=ResetEventStatus, queue-length=1
        operation=PrestoreFreezeFrame, queue-length=1
        operation=ClearPrestoredFreezeFrame, queue-length=1
        operation=ResetEventDebounceStatus, queue-length=1
    provide port EvtInfo_DEM_DTC_EPS_All_Node_Missing: provided-interface=DiagnosticInfo
      provided-com-specs:
        operation=GetEventStatus, queue-length=1
        operation=GetEventFailed, queue-length=1
        operation=GetEventTested, queue-length=1
        operation=GetDTCOfEvent, queue-length=1
        operation=GetFaultDetectionCounter, queue-length=1
        operation=GetEventFreezeFrameData, queue-length=1
        operation=GetEventExtendedDataRecord, queue-length=1
    require port CBStatusEvt_DEM_DTC_EPS_All_Node_Missing_1: required-interface=CallbackEventStatusChange
    provide port Event_DEM_DTC_VCU_Message_Alive_Counter_Error: provided-interface=DiagnosticMonitor
      provided-com-specs:
        operation=SetEventStatus, queue-length=1
        operation=ResetEventStatus, queue-length=1
        operation=PrestoreFreezeFrame, queue-length=1
        operation=ClearPrestoredFreezeFrame, queue-length=1
        operation=ResetEventDebounceStatus, queue-length=1
    provide port EvtInfo_DEM_DTC_VCU_Message_Alive_Counter_Error: provided-interface=DiagnosticInfo
      provided-com-specs:
        operation=GetEventStatus, queue-length=1
        operation=GetEventFailed, queue-length=1
        operation=GetEventTested, queue-length=1
        operation=GetDTCOfEvent, queue-length=1
        operation=GetFaultDetectionCounter, queue-length=1
        operation=GetEventFreezeFrameData, queue-length=1
        operation=GetEventExtendedDataRecord, queue-length=1
    require port CBStatusEvt_DEM_DTC_VCU_Message_Alive_Counter_Error_1: required-interface=CallbackEventStatusChange
    provide port Event_DEM_DTC_ESP_Message_Alive_Counter_Error: provided-interface=DiagnosticMonitor
      provided-com-specs:
        operation=SetEventStatus, queue-length=1
        operation=ResetEventStatus, queue-length=1
        operation=PrestoreFreezeFrame, queue-length=1
        operation=ClearPrestoredFreezeFrame, queue-length=1
        operation=ResetEventDebounceStatus, queue-length=1
    provide port EvtInfo_DEM_DTC_ESP_Message_Alive_Counter_Error: provided-interface=DiagnosticInfo
      provided-com-specs:
        operation=GetEventStatus, queue-length=1
        operation=GetEventFailed, queue-length=1
        operation=GetEventTested, queue-length=1
        operation=GetDTCOfEvent, queue-length=1
        operation=GetFaultDetectionCounter, queue-length=1
        operation=GetEventFreezeFrameData, queue-length=1
        operation=GetEventExtendedDataRecord, queue-length=1
    require port CBStatusEvt_DEM_DTC_ESP_Message_Alive_Counter_Error_1: required-interface=CallbackEventStatusChange
    provide port Event_DEM_DTC_EPS_Message_Alive_Counter_Error_10ms: provided-interface=DiagnosticMonitor
      provided-com-specs:
        operation=SetEventStatus, queue-length=1
        operation=ResetEventStatus, queue-length=1
        operation=PrestoreFreezeFrame, queue-length=1
        operation=ClearPrestoredFreezeFrame, queue-length=1
        operation=ResetEventDebounceStatus, queue-length=1
    provide port EvtInfo_DEM_DTC_EPS_Message_Alive_Counter_Error_10ms: provided-interface=DiagnosticInfo
      provided-com-specs:
        operation=GetEventStatus, queue-length=1
        operation=GetEventFailed, queue-length=1
        operation=GetEventTested, queue-length=1
        operation=GetDTCOfEvent, queue-length=1
        operation=GetFaultDetectionCounter, queue-length=1
        operation=GetEventFreezeFrameData, queue-length=1
        operation=GetEventExtendedDataRecord, queue-length=1
    require port CBStatusEvt_DEM_DTC_EPS_Message_Alive_Counter_Error_10ms_1: required-interface=CallbackEventStatusChange
    provide port Event_DEM_DTC_Front_Radar_Alive_Counter_Error: provided-interface=DiagnosticMonitor
      provided-com-specs:
        operation=SetEventStatus, queue-length=1
        operation=ResetEventStatus, queue-length=1
        operation=PrestoreFreezeFrame, queue-length=1
        operation=ClearPrestoredFreezeFrame, queue-length=1
        operation=ResetEventDebounceStatus, queue-length=1
    provide port EvtInfo_DEM_DTC_Front_Radar_Alive_Counter_Error: provided-interface=DiagnosticInfo
      provided-com-specs:
        operation=GetEventStatus, queue-length=1
        operation=GetEventFailed, queue-length=1
        operation=GetEventTested, queue-length=1
        operation=GetDTCOfEvent, queue-length=1
        operation=GetFaultDetectionCounter, queue-length=1
        operation=GetEventFreezeFrameData, queue-length=1
        operation=GetEventExtendedDataRecord, queue-length=1
    require port CBStatusEvt_DEM_DTC_Front_Radar_Alive_Counter_Error_1: required-interface=CallbackEventStatusChange
    provide port Event_DEM_DTC_ESP_ABS_Fault: provided-interface=DiagnosticMonitor
      provided-com-specs:
        operation=SetEventStatus, queue-length=1
        operation=ResetEventStatus, queue-length=1
        operation=PrestoreFreezeFrame, queue-length=1
        operation=ClearPrestoredFreezeFrame, queue-length=1
        operation=ResetEventDebounceStatus, queue-length=1
    provide port EvtInfo_DEM_DTC_ESP_ABS_Fault: provided-interface=DiagnosticInfo
      provided-com-specs:
        operation=GetEventStatus, queue-length=1
        operation=GetEventFailed, queue-length=1
        operation=GetEventTested, queue-length=1
        operation=GetDTCOfEvent, queue-length=1
        operation=GetFaultDetectionCounter, queue-length=1
        operation=GetEventFreezeFrameData, queue-length=1
        operation=GetEventExtendedDataRecord, queue-length=1
    require port CBStatusEvt_DEM_DTC_ESP_ABS_Fault_1: required-interface=CallbackEventStatusChange
    provide port Event_DEM_DTC_ESP_TCS_Fault: provided-interface=DiagnosticMonitor
      provided-com-specs:
        operation=SetEventStatus, queue-length=1
        operation=ResetEventStatus, queue-length=1
        operation=PrestoreFreezeFrame, queue-length=1
        operation=ClearPrestoredFreezeFrame, queue-length=1
        operation=ResetEventDebounceStatus, queue-length=1
    provide port EvtInfo_DEM_DTC_ESP_TCS_Fault: provided-interface=DiagnosticInfo
      provided-com-specs:
        operation=GetEventStatus, queue-length=1
        operation=GetEventFailed, queue-length=1
        operation=GetEventTested, queue-length=1
        operation=GetDTCOfEvent, queue-length=1
        operation=GetFaultDetectionCounter, queue-length=1
        operation=GetEventFreezeFrameData, queue-length=1
        operation=GetEventExtendedDataRecord, queue-length=1
    require port CBStatusEvt_DEM_DTC_ESP_TCS_Fault_1: required-interface=CallbackEventStatusChange
    provide port Event_DEM_DTC_ESP_ABA_NOT_Available: provided-interface=DiagnosticMonitor
      provided-com-specs:
        operation=SetEventStatus, queue-length=1
        operation=ResetEventStatus, queue-length=1
        operation=PrestoreFreezeFrame, queue-length=1
        operation=ClearPrestoredFreezeFrame, queue-length=1
        operation=ResetEventDebounceStatus, queue-length=1
    provide port EvtInfo_DEM_DTC_ESP_ABA_NOT_Available: provided-interface=DiagnosticInfo
      provided-com-specs:
        operation=GetEventStatus, queue-length=1
        operation=GetEventFailed, queue-length=1
        operation=GetEventTested, queue-length=1
        operation=GetDTCOfEvent, queue-length=1
        operation=GetFaultDetectionCounter, queue-length=1
        operation=GetEventFreezeFrameData, queue-length=1
        operation=GetEventExtendedDataRecord, queue-length=1
    require port CBStatusEvt_DEM_DTC_ESP_ABA_NOT_Available_1: required-interface=CallbackEventStatusChange
    provide port Event_DEM_DTC_ESP_AEB_NOT_Available: provided-interface=DiagnosticMonitor
      provided-com-specs:
        operation=SetEventStatus, queue-length=1
        operation=ResetEventStatus, queue-length=1
        operation=PrestoreFreezeFrame, queue-length=1
        operation=ClearPrestoredFreezeFrame, queue-length=1
        operation=ResetEventDebounceStatus, queue-length=1
    provide port EvtInfo_DEM_DTC_ESP_AEB_NOT_Available: provided-interface=DiagnosticInfo
      provided-com-specs:
        operation=GetEventStatus, queue-length=1
        operation=GetEventFailed, queue-length=1
        operation=GetEventTested, queue-length=1
        operation=GetDTCOfEvent, queue-length=1
        operation=GetFaultDetectionCounter, queue-length=1
        operation=GetEventFreezeFrameData, queue-length=1
        operation=GetEventExtendedDataRecord, queue-length=1
    require port CBStatusEvt_DEM_DTC_ESP_AEB_NOT_Available_1: required-interface=CallbackEventStatusChange
    provide port Event_DEM_DTC_ESP_AWB_NOT_Available: provided-interface=DiagnosticMonitor
      provided-com-specs:
        operation=SetEventStatus, queue-length=1
        operation=ResetEventStatus, queue-length=1
        operation=PrestoreFreezeFrame, queue-length=1
        operation=ClearPrestoredFreezeFrame, queue-length=1
        operation=ResetEventDebounceStatus, queue-length=1
    provide port EvtInfo_DEM_DTC_ESP_AWB_NOT_Available: provided-interface=DiagnosticInfo
      provided-com-specs:
        operation=GetEventStatus, queue-length=1
        operation=GetEventFailed, queue-length=1
        operation=GetEventTested, queue-length=1
        operation=GetDTCOfEvent, queue-length=1
        operation=GetFaultDetectionCounter, queue-length=1
        operation=GetEventFreezeFrameData, queue-length=1
        operation=GetEventExtendedDataRecord, queue-length=1
    require port CBStatusEvt_DEM_DTC_ESP_AWB_NOT_Available_1: required-interface=CallbackEventStatusChange
    provide port Event_DEM_DTC_IB_Brk_Pedl_Invld: provided-interface=DiagnosticMonitor
      provided-com-specs:
        operation=SetEventStatus, queue-length=1
        operation=ResetEventStatus, queue-length=1
        operation=PrestoreFreezeFrame, queue-length=1
        operation=ClearPrestoredFreezeFrame, queue-length=1
        operation=ResetEventDebounceStatus, queue-length=1
    provide port EvtInfo_DEM_DTC_IB_Brk_Pedl_Invld: provided-interface=DiagnosticInfo
      provided-com-specs:
        operation=GetEventStatus, queue-length=1
        operation=GetEventFailed, queue-length=1
        operation=GetEventTested, queue-length=1
        operation=GetDTCOfEvent, queue-length=1
        operation=GetFaultDetectionCounter, queue-length=1
        operation=GetEventFreezeFrameData, queue-length=1
        operation=GetEventExtendedDataRecord, queue-length=1
    require port CBStatusEvt_DEM_DTC_IB_Brk_Pedl_Invld_1: required-interface=CallbackEventStatusChange
    provide port Event_DEM_DTC_EPS_Actual_Torsion_Torq_Invld: provided-interface=DiagnosticMonitor
      provided-com-specs:
        operation=SetEventStatus, queue-length=1
        operation=ResetEventStatus, queue-length=1
        operation=PrestoreFreezeFrame, queue-length=1
        operation=ClearPrestoredFreezeFrame, queue-length=1
        operation=ResetEventDebounceStatus, queue-length=1
    provide port EvtInfo_DEM_DTC_EPS_Actual_Torsion_Torq_Invld: provided-interface=DiagnosticInfo
      provided-com-specs:
        operation=GetEventStatus, queue-length=1
        operation=GetEventFailed, queue-length=1
        operation=GetEventTested, queue-length=1
        operation=GetDTCOfEvent, queue-length=1
        operation=GetFaultDetectionCounter, queue-length=1
        operation=GetEventFreezeFrameData, queue-length=1
        operation=GetEventExtendedDataRecord, queue-length=1
    require port CBStatusEvt_DEM_DTC_EPS_Actual_Torsion_Torq_Invld_1: required-interface=CallbackEventStatusChange
    provide port Event_DEM_DTC_EPS_Actual_Motor_Invld: provided-interface=DiagnosticMonitor
      provided-com-specs:
        operation=SetEventStatus, queue-length=1
        operation=ResetEventStatus, queue-length=1
        operation=PrestoreFreezeFrame, queue-length=1
        operation=ClearPrestoredFreezeFrame, queue-length=1
        operation=ResetEventDebounceStatus, queue-length=1
    provide port EvtInfo_DEM_DTC_EPS_Actual_Motor_Invld: provided-interface=DiagnosticInfo
      provided-com-specs:
        operation=GetEventStatus, queue-length=1
        operation=GetEventFailed, queue-length=1
        operation=GetEventTested, queue-length=1
        operation=GetDTCOfEvent, queue-length=1
        operation=GetFaultDetectionCounter, queue-length=1
        operation=GetEventFreezeFrameData, queue-length=1
        operation=GetEventExtendedDataRecord, queue-length=1
    require port CBStatusEvt_DEM_DTC_EPS_Actual_Motor_Invld_1: required-interface=CallbackEventStatusChange
    provide port Event_DEM_DTC_EPS_Steer_AgSens_Fault: provided-interface=DiagnosticMonitor
      provided-com-specs:
        operation=SetEventStatus, queue-length=1
        operation=ResetEventStatus, queue-length=1
        operation=PrestoreFreezeFrame, queue-length=1
        operation=ClearPrestoredFreezeFrame, queue-length=1
        operation=ResetEventDebounceStatus, queue-length=1
    provide port EvtInfo_DEM_DTC_EPS_Steer_AgSens_Fault: provided-interface=DiagnosticInfo
      provided-com-specs:
        operation=GetEventStatus, queue-length=1
        operation=GetEventFailed, queue-length=1
        operation=GetEventTested, queue-length=1
        operation=GetDTCOfEvent, queue-length=1
        operation=GetFaultDetectionCounter, queue-length=1
        operation=GetEventFreezeFrameData, queue-length=1
        operation=GetEventExtendedDataRecord, queue-length=1
    require port CBStatusEvt_DEM_DTC_EPS_Steer_AgSens_Fault_1: required-interface=CallbackEventStatusChange
    provide port Event_DEM_DTC_SRS_Drvr_BucSwt_Invld: provided-interface=DiagnosticMonitor
      provided-com-specs:
        operation=SetEventStatus, queue-length=1
        operation=ResetEventStatus, queue-length=1
        operation=PrestoreFreezeFrame, queue-length=1
        operation=ClearPrestoredFreezeFrame, queue-length=1
        operation=ResetEventDebounceStatus, queue-length=1
    provide port EvtInfo_DEM_DTC_SRS_Drvr_BucSwt_Invld: provided-interface=DiagnosticInfo
      provided-com-specs:
        operation=GetEventStatus, queue-length=1
        operation=GetEventFailed, queue-length=1
        operation=GetEventTested, queue-length=1
        operation=GetDTCOfEvent, queue-length=1
        operation=GetFaultDetectionCounter, queue-length=1
        operation=GetEventFreezeFrameData, queue-length=1
        operation=GetEventExtendedDataRecord, queue-length=1
    require port CBStatusEvt_DEM_DTC_SRS_Drvr_BucSwt_Invld_1: required-interface=CallbackEventStatusChange
    provide port Event_DEM_DTC_EPS_Pinionang_Invld: provided-interface=DiagnosticMonitor
      provided-com-specs:
        operation=SetEventStatus, queue-length=1
        operation=ResetEventStatus, queue-length=1
        operation=PrestoreFreezeFrame, queue-length=1
        operation=ClearPrestoredFreezeFrame, queue-length=1
        operation=ResetEventDebounceStatus, queue-length=1
    provide port EvtInfo_DEM_DTC_EPS_Pinionang_Invld: provided-interface=DiagnosticInfo
      provided-com-specs:
        operation=GetEventStatus, queue-length=1
        operation=GetEventFailed, queue-length=1
        operation=GetEventTested, queue-length=1
        operation=GetDTCOfEvent, queue-length=1
        operation=GetFaultDetectionCounter, queue-length=1
        operation=GetEventFreezeFrameData, queue-length=1
        operation=GetEventExtendedDataRecord, queue-length=1
    require port CBStatusEvt_DEM_DTC_EPS_Pinionang_Invld_1: required-interface=CallbackEventStatusChange
    provide port Event_DEM_DTC_EPS_Pinionang_Fault: provided-interface=DiagnosticMonitor
      provided-com-specs:
        operation=SetEventStatus, queue-length=1
        operation=ResetEventStatus, queue-length=1
        operation=PrestoreFreezeFrame, queue-length=1
        operation=ClearPrestoredFreezeFrame, queue-length=1
        operation=ResetEventDebounceStatus, queue-length=1
    provide port EvtInfo_DEM_DTC_EPS_Pinionang_Fault: provided-interface=DiagnosticInfo
      provided-com-specs:
        operation=GetEventStatus, queue-length=1
        operation=GetEventFailed, queue-length=1
        operation=GetEventTested, queue-length=1
        operation=GetDTCOfEvent, queue-length=1
        operation=GetFaultDetectionCounter, queue-length=1
        operation=GetEventFreezeFrameData, queue-length=1
        operation=GetEventExtendedDataRecord, queue-length=1
    require port CBStatusEvt_DEM_DTC_EPS_Pinionang_Fault_1: required-interface=CallbackEventStatusChange
    provide port Event_DEM_DTC_EPS_APA_Epas_Fault: provided-interface=DiagnosticMonitor
      provided-com-specs:
        operation=SetEventStatus, queue-length=1
        operation=ResetEventStatus, queue-length=1
        operation=PrestoreFreezeFrame, queue-length=1
        operation=ClearPrestoredFreezeFrame, queue-length=1
        operation=ResetEventDebounceStatus, queue-length=1
    provide port EvtInfo_DEM_DTC_EPS_APA_Epas_Fault: provided-interface=DiagnosticInfo
      provided-com-specs:
        operation=GetEventStatus, queue-length=1
        operation=GetEventFailed, queue-length=1
        operation=GetEventTested, queue-length=1
        operation=GetDTCOfEvent, queue-length=1
        operation=GetFaultDetectionCounter, queue-length=1
        operation=GetEventFreezeFrameData, queue-length=1
        operation=GetEventExtendedDataRecord, queue-length=1
    require port CBStatusEvt_DEM_DTC_EPS_APA_Epas_Fault_1: required-interface=CallbackEventStatusChange
    provide port Event_DEM_DTC_BCM_EmgyLi_Fault: provided-interface=DiagnosticMonitor
      provided-com-specs:
        operation=SetEventStatus, queue-length=1
        operation=ResetEventStatus, queue-length=1
        operation=PrestoreFreezeFrame, queue-length=1
        operation=ClearPrestoredFreezeFrame, queue-length=1
        operation=ResetEventDebounceStatus, queue-length=1
    provide port EvtInfo_DEM_DTC_BCM_EmgyLi_Fault: provided-interface=DiagnosticInfo
      provided-com-specs:
        operation=GetEventStatus, queue-length=1
        operation=GetEventFailed, queue-length=1
        operation=GetEventTested, queue-length=1
        operation=GetDTCOfEvent, queue-length=1
        operation=GetFaultDetectionCounter, queue-length=1
        operation=GetEventFreezeFrameData, queue-length=1
        operation=GetEventExtendedDataRecord, queue-length=1
    require port CBStatusEvt_DEM_DTC_BCM_EmgyLi_Fault_1: required-interface=CallbackEventStatusChange
    provide port Event_DEM_DTC_BCM_All_Node_Missing: provided-interface=DiagnosticMonitor
      provided-com-specs:
        operation=SetEventStatus, queue-length=1
        operation=ResetEventStatus, queue-length=1
        operation=PrestoreFreezeFrame, queue-length=1
        operation=ClearPrestoredFreezeFrame, queue-length=1
        operation=ResetEventDebounceStatus, queue-length=1
    provide port EvtInfo_DEM_DTC_BCM_All_Node_Missing: provided-interface=DiagnosticInfo
      provided-com-specs:
        operation=GetEventStatus, queue-length=1
        operation=GetEventFailed, queue-length=1
        operation=GetEventTested, queue-length=1
        operation=GetDTCOfEvent, queue-length=1
        operation=GetFaultDetectionCounter, queue-length=1
        operation=GetEventFreezeFrameData, queue-length=1
        operation=GetEventExtendedDataRecord, queue-length=1
    require port CBStatusEvt_DEM_DTC_BCM_All_Node_Missing_1: required-interface=CallbackEventStatusChange
    provide port Event_DEM_DTC_BCM_Message_Alive_Counter_Error_40ms: provided-interface=DiagnosticMonitor
      provided-com-specs:
        operation=SetEventStatus, queue-length=1
        operation=ResetEventStatus, queue-length=1
        operation=PrestoreFreezeFrame, queue-length=1
        operation=ClearPrestoredFreezeFrame, queue-length=1
        operation=ResetEventDebounceStatus, queue-length=1
    provide port EvtInfo_DEM_DTC_BCM_Message_Alive_Counter_Error_40ms: provided-interface=DiagnosticInfo
      provided-com-specs:
        operation=GetEventStatus, queue-length=1
        operation=GetEventFailed, queue-length=1
        operation=GetEventTested, queue-length=1
        operation=GetDTCOfEvent, queue-length=1
        operation=GetFaultDetectionCounter, queue-length=1
        operation=GetEventFreezeFrameData, queue-length=1
        operation=GetEventExtendedDataRecord, queue-length=1
    require port CBStatusEvt_DEM_DTC_BCM_Message_Alive_Counter_Error_40ms_1: required-interface=CallbackEventStatusChange
    provide port Event_DEM_DTC_J3_Camera_Blockage: provided-interface=DiagnosticMonitor
      provided-com-specs:
        operation=SetEventStatus, queue-length=1
        operation=ResetEventStatus, queue-length=1
        operation=PrestoreFreezeFrame, queue-length=1
        operation=ClearPrestoredFreezeFrame, queue-length=1
        operation=ResetEventDebounceStatus, queue-length=1
    provide port EvtInfo_DEM_DTC_J3_Camera_Blockage: provided-interface=DiagnosticInfo
      provided-com-specs:
        operation=GetEventStatus, queue-length=1
        operation=GetEventFailed, queue-length=1
        operation=GetEventTested, queue-length=1
        operation=GetDTCOfEvent, queue-length=1
        operation=GetFaultDetectionCounter, queue-length=1
        operation=GetEventFreezeFrameData, queue-length=1
        operation=GetEventExtendedDataRecord, queue-length=1
    require port CBStatusEvt_DEM_DTC_J3_Camera_Blockage_1: required-interface=CallbackEventStatusChange
    provide port EvtInfo_DEM_DTC_Private_CAN_Bus_Off: provided-interface=DiagnosticInfo
      provided-com-specs:
        operation=GetEventStatus, queue-length=1
        operation=GetEventFailed, queue-length=1
        operation=GetEventTested, queue-length=1
        operation=GetDTCOfEvent, queue-length=1
        operation=GetFaultDetectionCounter, queue-length=1
        operation=GetEventFreezeFrameData, queue-length=1
        operation=GetEventExtendedDataRecord, queue-length=1
    require port CBStatusEvt_DEM_DTC_Private_CAN_Bus_Off_1: required-interface=CallbackEventStatusChange
    provide port EvtInfo_DEM_DTC_Public_CAN_Bus_Off: provided-interface=DiagnosticInfo
      provided-com-specs:
        operation=GetEventStatus, queue-length=1
        operation=GetEventFailed, queue-length=1
        operation=GetEventTested, queue-length=1
        operation=GetDTCOfEvent, queue-length=1
        operation=GetFaultDetectionCounter, queue-length=1
        operation=GetEventFreezeFrameData, queue-length=1
        operation=GetEventExtendedDataRecord, queue-length=1
    require port CBStatusEvt_DEM_DTC_Public_CAN_Bus_Off_1: required-interface=CallbackEventStatusChange
    7 x provide port:
      Event_DEM_DTC_Ethernet_Unexpected_Link_Down: provided-interface=DiagnosticMonitor
        provided-com-specs:
          operation=SetEventStatus, queue-length=1
          operation=ResetEventStatus, queue-length=1
          operation=PrestoreFreezeFrame, queue-length=1
          operation=ClearPrestoredFreezeFrame, queue-length=1
          operation=ResetEventDebounceStatus, queue-length=1
      EvtInfo_DEM_DTC_Ethernet_Unexpected_Link_Down: provided-interface=DiagnosticInfo
        provided-com-specs:
          operation=GetEventStatus, queue-length=1
          operation=GetEventFailed, queue-length=1
          operation=GetEventTested, queue-length=1
          operation=GetDTCOfEvent, queue-length=1
          operation=GetFaultDetectionCounter, queue-length=1
          operation=GetEventFreezeFrameData, queue-length=1
          operation=GetEventExtendedDataRecord, queue-length=1
      Event_DEM_DTC_J3_SoC_ETH_IP_Ubnormal: provided-interface=DiagnosticMonitor
        provided-com-specs:
          operation=SetEventStatus, queue-length=1
          operation=ResetEventStatus, queue-length=1
          operation=PrestoreFreezeFrame, queue-length=1
          operation=ClearPrestoredFreezeFrame, queue-length=1
          operation=ResetEventDebounceStatus, queue-length=1
      EvtInfo_DEM_DTC_J3_SoC_ETH_IP_Ubnormal: provided-interface=DiagnosticInfo
        provided-com-specs:
          operation=GetEventStatus, queue-length=1
          operation=GetEventFailed, queue-length=1
          operation=GetEventTested, queue-length=1
          operation=GetDTCOfEvent, queue-length=1
          operation=GetFaultDetectionCounter, queue-length=1
          operation=GetEventFreezeFrameData, queue-length=1
          operation=GetEventExtendedDataRecord, queue-length=1
      EvtInfo_ECUM_E_RAM_CHECK_FAILED: provided-interface=DiagnosticInfo
        provided-com-specs:
          operation=GetEventStatus, queue-length=1
          operation=GetEventFailed, queue-length=1
          operation=GetEventTested, queue-length=1
          operation=GetDTCOfEvent, queue-length=1
          operation=GetFaultDetectionCounter, queue-length=1
          operation=GetEventFreezeFrameData, queue-length=1
          operation=GetEventExtendedDataRecord, queue-length=1
      Event_DEM_DTC_J3_SOC_Safetylib_Error: provided-interface=DiagnosticMonitor
        provided-com-specs:
          operation=SetEventStatus, queue-length=1
          operation=ResetEventStatus, queue-length=1
          operation=PrestoreFreezeFrame, queue-length=1
          operation=ClearPrestoredFreezeFrame, queue-length=1
          operation=ResetEventDebounceStatus, queue-length=1
      EvtInfo_DEM_DTC_J3_SOC_Safetylib_Error: provided-interface=DiagnosticInfo
        provided-com-specs:
          operation=GetEventStatus, queue-length=1
          operation=GetEventFailed, queue-length=1
          operation=GetEventTested, queue-length=1
          operation=GetDTCOfEvent, queue-length=1
          operation=GetFaultDetectionCounter, queue-length=1
          operation=GetEventFreezeFrameData, queue-length=1
          operation=GetEventExtendedDataRecord, queue-length=1
    require port CBStatusEvt_DEM_DTC_J3_SOC_Safetylib_Error_1: required-interface=CallbackEventStatusChange
    provide port Event_DEM_DTC_EPS_Steering_wheel_vibration_failure: provided-interface=DiagnosticMonitor
      provided-com-specs:
        operation=SetEventStatus, queue-length=1
        operation=ResetEventStatus, queue-length=1
        operation=PrestoreFreezeFrame, queue-length=1
        operation=ClearPrestoredFreezeFrame, queue-length=1
        operation=ResetEventDebounceStatus, queue-length=1
    provide port EvtInfo_DEM_DTC_EPS_Steering_wheel_vibration_failure: provided-interface=DiagnosticInfo
      provided-com-specs:
        operation=GetEventStatus, queue-length=1
        operation=GetEventFailed, queue-length=1
        operation=GetEventTested, queue-length=1
        operation=GetDTCOfEvent, queue-length=1
        operation=GetFaultDetectionCounter, queue-length=1
        operation=GetEventFreezeFrameData, queue-length=1
        operation=GetEventExtendedDataRecord, queue-length=1
    require port CBStatusEvt_DEM_DTC_EPS_Steering_wheel_vibration_failure_1: required-interface=CallbackEventStatusChange
    provide port Event_DEM_DTC_EPS_Driver_hand_torque_invalid: provided-interface=DiagnosticMonitor
      provided-com-specs:
        operation=SetEventStatus, queue-length=1
        operation=ResetEventStatus, queue-length=1
        operation=PrestoreFreezeFrame, queue-length=1
        operation=ClearPrestoredFreezeFrame, queue-length=1
        operation=ResetEventDebounceStatus, queue-length=1
    provide port EvtInfo_DEM_DTC_EPS_Driver_hand_torque_invalid: provided-interface=DiagnosticInfo
      provided-com-specs:
        operation=GetEventStatus, queue-length=1
        operation=GetEventFailed, queue-length=1
        operation=GetEventTested, queue-length=1
        operation=GetDTCOfEvent, queue-length=1
        operation=GetFaultDetectionCounter, queue-length=1
        operation=GetEventFreezeFrameData, queue-length=1
        operation=GetEventExtendedDataRecord, queue-length=1
    require port CBStatusEvt_DEM_DTC_EPS_Driver_hand_torque_invalid_1: required-interface=CallbackEventStatusChange
    provide port Event_DEM_DTC_IP_warning_invalid: provided-interface=DiagnosticMonitor
      provided-com-specs:
        operation=SetEventStatus, queue-length=1
        operation=ResetEventStatus, queue-length=1
        operation=PrestoreFreezeFrame, queue-length=1
        operation=ClearPrestoredFreezeFrame, queue-length=1
        operation=ResetEventDebounceStatus, queue-length=1
    provide port EvtInfo_DEM_DTC_IP_warning_invalid: provided-interface=DiagnosticInfo
      provided-com-specs:
        operation=GetEventStatus, queue-length=1
        operation=GetEventFailed, queue-length=1
        operation=GetEventTested, queue-length=1
        operation=GetDTCOfEvent, queue-length=1
        operation=GetFaultDetectionCounter, queue-length=1
        operation=GetEventFreezeFrameData, queue-length=1
        operation=GetEventExtendedDataRecord, queue-length=1
    require port CBStatusEvt_DEM_DTC_IP_warning_invalid_1: required-interface=CallbackEventStatusChange
    provide port Event_DEM_DTC_IP_node_missing: provided-interface=DiagnosticMonitor
      provided-com-specs:
        operation=SetEventStatus, queue-length=1
        operation=ResetEventStatus, queue-length=1
        operation=PrestoreFreezeFrame, queue-length=1
        operation=ClearPrestoredFreezeFrame, queue-length=1
        operation=ResetEventDebounceStatus, queue-length=1
    provide port EvtInfo_DEM_DTC_IP_node_missing: provided-interface=DiagnosticInfo
      provided-com-specs:
        operation=GetEventStatus, queue-length=1
        operation=GetEventFailed, queue-length=1
        operation=GetEventTested, queue-length=1
        operation=GetDTCOfEvent, queue-length=1
        operation=GetFaultDetectionCounter, queue-length=1
        operation=GetEventFreezeFrameData, queue-length=1
        operation=GetEventExtendedDataRecord, queue-length=1
    require port CBStatusEvt_DEM_DTC_IP_node_missing_1: required-interface=CallbackEventStatusChange
    provide port Event_DEM_DTC_IP_message_alive_counter_error: provided-interface=DiagnosticMonitor
      provided-com-specs:
        operation=SetEventStatus, queue-length=1
        operation=ResetEventStatus, queue-length=1
        operation=PrestoreFreezeFrame, queue-length=1
        operation=ClearPrestoredFreezeFrame, queue-length=1
        operation=ResetEventDebounceStatus, queue-length=1
    provide port EvtInfo_DEM_DTC_IP_message_alive_counter_error: provided-interface=DiagnosticInfo
      provided-com-specs:
        operation=GetEventStatus, queue-length=1
        operation=GetEventFailed, queue-length=1
        operation=GetEventTested, queue-length=1
        operation=GetDTCOfEvent, queue-length=1
        operation=GetFaultDetectionCounter, queue-length=1
        operation=GetEventFreezeFrameData, queue-length=1
        operation=GetEventExtendedDataRecord, queue-length=1
    require port CBStatusEvt_DEM_DTC_IP_message_alive_counter_error_1: required-interface=CallbackEventStatusChange
    provide port Event_DEM_DTC_Fradar_not_calibration_or_blockage: provided-interface=DiagnosticMonitor
      provided-com-specs:
        operation=SetEventStatus, queue-length=1
        operation=ResetEventStatus, queue-length=1
        operation=PrestoreFreezeFrame, queue-length=1
        operation=ClearPrestoredFreezeFrame, queue-length=1
        operation=ResetEventDebounceStatus, queue-length=1
    provide port EvtInfo_DEM_DTC_Fradar_not_calibration_or_blockage: provided-interface=DiagnosticInfo
      provided-com-specs:
        operation=GetEventStatus, queue-length=1
        operation=GetEventFailed, queue-length=1
        operation=GetEventTested, queue-length=1
        operation=GetDTCOfEvent, queue-length=1
        operation=GetFaultDetectionCounter, queue-length=1
        operation=GetEventFreezeFrameData, queue-length=1
        operation=GetEventExtendedDataRecord, queue-length=1
    require port CBStatusEvt_DEM_DTC_Fradar_not_calibration_or_blockage_1: required-interface=CallbackEventStatusChange
    provide port Event_DEM_DTC_Fradar_hardware_error: provided-interface=DiagnosticMonitor
      provided-com-specs:
        operation=SetEventStatus, queue-length=1
        operation=ResetEventStatus, queue-length=1
        operation=PrestoreFreezeFrame, queue-length=1
        operation=ClearPrestoredFreezeFrame, queue-length=1
        operation=ResetEventDebounceStatus, queue-length=1
    provide port EvtInfo_DEM_DTC_Fradar_hardware_error: provided-interface=DiagnosticInfo
      provided-com-specs:
        operation=GetEventStatus, queue-length=1
        operation=GetEventFailed, queue-length=1
        operation=GetEventTested, queue-length=1
        operation=GetDTCOfEvent, queue-length=1
        operation=GetFaultDetectionCounter, queue-length=1
        operation=GetEventFreezeFrameData, queue-length=1
        operation=GetEventExtendedDataRecord, queue-length=1
    require port CBStatusEvt_DEM_DTC_Fradar_hardware_error_1: required-interface=CallbackEventStatusChange
    provide port Event_DEM_DTC_SRS_All_Node_Missing: provided-interface=DiagnosticMonitor
      provided-com-specs:
        operation=SetEventStatus, queue-length=1
        operation=ResetEventStatus, queue-length=1
        operation=PrestoreFreezeFrame, queue-length=1
        operation=ClearPrestoredFreezeFrame, queue-length=1
        operation=ResetEventDebounceStatus, queue-length=1
    provide port EvtInfo_DEM_DTC_SRS_All_Node_Missing: provided-interface=DiagnosticInfo
      provided-com-specs:
        operation=GetEventStatus, queue-length=1
        operation=GetEventFailed, queue-length=1
        operation=GetEventTested, queue-length=1
        operation=GetDTCOfEvent, queue-length=1
        operation=GetFaultDetectionCounter, queue-length=1
        operation=GetEventFreezeFrameData, queue-length=1
        operation=GetEventExtendedDataRecord, queue-length=1
    require port CBStatusEvt_DEM_DTC_SRS_All_Node_Missing_1: required-interface=CallbackEventStatusChange
    provide port Event_DEM_DTC_ADC_Message_Alive_Counter_Error: provided-interface=DiagnosticMonitor
      provided-com-specs:
        operation=SetEventStatus, queue-length=1
        operation=ResetEventStatus, queue-length=1
        operation=PrestoreFreezeFrame, queue-length=1
        operation=ClearPrestoredFreezeFrame, queue-length=1
        operation=ResetEventDebounceStatus, queue-length=1
    provide port EvtInfo_DEM_DTC_ADC_Message_Alive_Counter_Error: provided-interface=DiagnosticInfo
      provided-com-specs:
        operation=GetEventStatus, queue-length=1
        operation=GetEventFailed, queue-length=1
        operation=GetEventTested, queue-length=1
        operation=GetDTCOfEvent, queue-length=1
        operation=GetFaultDetectionCounter, queue-length=1
        operation=GetEventFreezeFrameData, queue-length=1
        operation=GetEventExtendedDataRecord, queue-length=1
    require port CBStatusEvt_DEM_DTC_ADC_Message_Alive_Counter_Error_1: required-interface=CallbackEventStatusChange
    provide port Event_DEM_DTC_RLR_Message_Alive_Counter_Error: provided-interface=DiagnosticMonitor
      provided-com-specs:
        operation=SetEventStatus, queue-length=1
        operation=ResetEventStatus, queue-length=1
        operation=PrestoreFreezeFrame, queue-length=1
        operation=ClearPrestoredFreezeFrame, queue-length=1
        operation=ResetEventDebounceStatus, queue-length=1
    provide port EvtInfo_DEM_DTC_RLR_Message_Alive_Counter_Error: provided-interface=DiagnosticInfo
      provided-com-specs:
        operation=GetEventStatus, queue-length=1
        operation=GetEventFailed, queue-length=1
        operation=GetEventTested, queue-length=1
        operation=GetDTCOfEvent, queue-length=1
        operation=GetFaultDetectionCounter, queue-length=1
        operation=GetEventFreezeFrameData, queue-length=1
        operation=GetEventExtendedDataRecord, queue-length=1
    require port CBStatusEvt_DEM_DTC_RLR_Message_Alive_Counter_Error_1: required-interface=CallbackEventStatusChange
    provide port Event_DEM_DTC_SRS_Message_Alive_Counter_Error: provided-interface=DiagnosticMonitor
      provided-com-specs:
        operation=SetEventStatus, queue-length=1
        operation=ResetEventStatus, queue-length=1
        operation=PrestoreFreezeFrame, queue-length=1
        operation=ClearPrestoredFreezeFrame, queue-length=1
        operation=ResetEventDebounceStatus, queue-length=1
    provide port EvtInfo_DEM_DTC_SRS_Message_Alive_Counter_Error: provided-interface=DiagnosticInfo
      provided-com-specs:
        operation=GetEventStatus, queue-length=1
        operation=GetEventFailed, queue-length=1
        operation=GetEventTested, queue-length=1
        operation=GetDTCOfEvent, queue-length=1
        operation=GetFaultDetectionCounter, queue-length=1
        operation=GetEventFreezeFrameData, queue-length=1
        operation=GetEventExtendedDataRecord, queue-length=1
    require port CBStatusEvt_DEM_DTC_SRS_Message_Alive_Counter_Error_1: required-interface=CallbackEventStatusChange
    provide port Event_DEM_DTC_EPS_Message_Alive_Counter_Error_20ms: provided-interface=DiagnosticMonitor
      provided-com-specs:
        operation=SetEventStatus, queue-length=1
        operation=ResetEventStatus, queue-length=1
        operation=PrestoreFreezeFrame, queue-length=1
        operation=ClearPrestoredFreezeFrame, queue-length=1
        operation=ResetEventDebounceStatus, queue-length=1
    provide port EvtInfo_DEM_DTC_EPS_Message_Alive_Counter_Error_20ms: provided-interface=DiagnosticInfo
      provided-com-specs:
        operation=GetEventStatus, queue-length=1
        operation=GetEventFailed, queue-length=1
        operation=GetEventTested, queue-length=1
        operation=GetDTCOfEvent, queue-length=1
        operation=GetFaultDetectionCounter, queue-length=1
        operation=GetEventFreezeFrameData, queue-length=1
        operation=GetEventExtendedDataRecord, queue-length=1
    require port CBStatusEvt_DEM_DTC_EPS_Message_Alive_Counter_Error_20ms_1: required-interface=CallbackEventStatusChange
    14 x provide port:
      Event_DEM_DTC_BCM_Message_Alive_Counter_Error_100ms: provided-interface=DiagnosticMonitor
        provided-com-specs:
          operation=SetEventStatus, queue-length=1
          operation=ResetEventStatus, queue-length=1
          operation=PrestoreFreezeFrame, queue-length=1
          operation=ClearPrestoredFreezeFrame, queue-length=1
          operation=ResetEventDebounceStatus, queue-length=1
      EvtInfo_DEM_DTC_BCM_Message_Alive_Counter_Error_100ms: provided-interface=DiagnosticInfo
        provided-com-specs:
          operation=GetEventStatus, queue-length=1
          operation=GetEventFailed, queue-length=1
          operation=GetEventTested, queue-length=1
          operation=GetDTCOfEvent, queue-length=1
          operation=GetFaultDetectionCounter, queue-length=1
          operation=GetEventFreezeFrameData, queue-length=1
          operation=GetEventExtendedDataRecord, queue-length=1
      Event_DEM_DTC_Private_CAN_Bus_Off_TOCAN: provided-interface=DiagnosticMonitor
        provided-com-specs:
          operation=SetEventStatus, queue-length=1
          operation=ResetEventStatus, queue-length=1
          operation=PrestoreFreezeFrame, queue-length=1
          operation=ClearPrestoredFreezeFrame, queue-length=1
          operation=ResetEventDebounceStatus, queue-length=1
      EvtInfo_DEM_DTC_Private_CAN_Bus_Off_TOCAN: provided-interface=DiagnosticInfo
        provided-com-specs:
          operation=GetEventStatus, queue-length=1
          operation=GetEventFailed, queue-length=1
          operation=GetEventTested, queue-length=1
          operation=GetDTCOfEvent, queue-length=1
          operation=GetFaultDetectionCounter, queue-length=1
          operation=GetEventFreezeFrameData, queue-length=1
          operation=GetEventExtendedDataRecord, queue-length=1
      Event_DEM_DTC_Public_CAN_Bus_Off_TOCAN: provided-interface=DiagnosticMonitor
        provided-com-specs:
          operation=SetEventStatus, queue-length=1
          operation=ResetEventStatus, queue-length=1
          operation=PrestoreFreezeFrame, queue-length=1
          operation=ClearPrestoredFreezeFrame, queue-length=1
          operation=ResetEventDebounceStatus, queue-length=1
      EvtInfo_DEM_DTC_Public_CAN_Bus_Off_TOCAN: provided-interface=DiagnosticInfo
        provided-com-specs:
          operation=GetEventStatus, queue-length=1
          operation=GetEventFailed, queue-length=1
          operation=GetEventTested, queue-length=1
          operation=GetDTCOfEvent, queue-length=1
          operation=GetFaultDetectionCounter, queue-length=1
          operation=GetEventFreezeFrameData, queue-length=1
          operation=GetEventExtendedDataRecord, queue-length=1
      Event_DEM_DTC_J3_Heavy_Rain_Detected: provided-interface=DiagnosticMonitor
        provided-com-specs:
          operation=SetEventStatus, queue-length=1
          operation=ResetEventStatus, queue-length=1
          operation=PrestoreFreezeFrame, queue-length=1
          operation=ClearPrestoredFreezeFrame, queue-length=1
          operation=ResetEventDebounceStatus, queue-length=1
      EvtInfo_DEM_DTC_J3_Heavy_Rain_Detected: provided-interface=DiagnosticInfo
        provided-com-specs:
          operation=GetEventStatus, queue-length=1
          operation=GetEventFailed, queue-length=1
          operation=GetEventTested, queue-length=1
          operation=GetDTCOfEvent, queue-length=1
          operation=GetFaultDetectionCounter, queue-length=1
          operation=GetEventFreezeFrameData, queue-length=1
          operation=GetEventExtendedDataRecord, queue-length=1
      Event_DEM_DTC_J3_Snow_Detected: provided-interface=DiagnosticMonitor
        provided-com-specs:
          operation=SetEventStatus, queue-length=1
          operation=ResetEventStatus, queue-length=1
          operation=PrestoreFreezeFrame, queue-length=1
          operation=ClearPrestoredFreezeFrame, queue-length=1
          operation=ResetEventDebounceStatus, queue-length=1
      EvtInfo_DEM_DTC_J3_Snow_Detected: provided-interface=DiagnosticInfo
        provided-com-specs:
          operation=GetEventStatus, queue-length=1
          operation=GetEventFailed, queue-length=1
          operation=GetEventTested, queue-length=1
          operation=GetDTCOfEvent, queue-length=1
          operation=GetFaultDetectionCounter, queue-length=1
          operation=GetEventFreezeFrameData, queue-length=1
          operation=GetEventExtendedDataRecord, queue-length=1
      Event_DEM_DTC_J3_Low_Sun_Detected: provided-interface=DiagnosticMonitor
        provided-com-specs:
          operation=SetEventStatus, queue-length=1
          operation=ResetEventStatus, queue-length=1
          operation=PrestoreFreezeFrame, queue-length=1
          operation=ClearPrestoredFreezeFrame, queue-length=1
          operation=ResetEventDebounceStatus, queue-length=1
      EvtInfo_DEM_DTC_J3_Low_Sun_Detected: provided-interface=DiagnosticInfo
        provided-com-specs:
          operation=GetEventStatus, queue-length=1
          operation=GetEventFailed, queue-length=1
          operation=GetEventTested, queue-length=1
          operation=GetDTCOfEvent, queue-length=1
          operation=GetFaultDetectionCounter, queue-length=1
          operation=GetEventFreezeFrameData, queue-length=1
          operation=GetEventExtendedDataRecord, queue-length=1
      Event_DEM_DTC_J3_SOC_System_Service_Error: provided-interface=DiagnosticMonitor
        provided-com-specs:
          operation=SetEventStatus, queue-length=1
          operation=ResetEventStatus, queue-length=1
          operation=PrestoreFreezeFrame, queue-length=1
          operation=ClearPrestoredFreezeFrame, queue-length=1
          operation=ResetEventDebounceStatus, queue-length=1
      EvtInfo_DEM_DTC_J3_SOC_System_Service_Error: provided-interface=DiagnosticInfo
        provided-com-specs:
          operation=GetEventStatus, queue-length=1
          operation=GetEventFailed, queue-length=1
          operation=GetEventTested, queue-length=1
          operation=GetDTCOfEvent, queue-length=1
          operation=GetFaultDetectionCounter, queue-length=1
          operation=GetEventFreezeFrameData, queue-length=1
          operation=GetEventExtendedDataRecord, queue-length=1
    require port CBStatusEvt_DEM_DTC_J3_SOC_System_Service_Error_1: required-interface=CallbackEventStatusChange
    provide port Event_DEM_DTC_J3_Camera_Error: provided-interface=DiagnosticMonitor
      provided-com-specs:
        operation=SetEventStatus, queue-length=1
        operation=ResetEventStatus, queue-length=1
        operation=PrestoreFreezeFrame, queue-length=1
        operation=ClearPrestoredFreezeFrame, queue-length=1
        operation=ResetEventDebounceStatus, queue-length=1
    provide port EvtInfo_DEM_DTC_J3_Camera_Error: provided-interface=DiagnosticInfo
      provided-com-specs:
        operation=GetEventStatus, queue-length=1
        operation=GetEventFailed, queue-length=1
        operation=GetEventTested, queue-length=1
        operation=GetDTCOfEvent, queue-length=1
        operation=GetFaultDetectionCounter, queue-length=1
        operation=GetEventFreezeFrameData, queue-length=1
        operation=GetEventExtendedDataRecord, queue-length=1
    require port CBStatusEvt_DEM_DTC_J3_Camera_Error_1: required-interface=CallbackEventStatusChange
    provide port Event_DEM_DTC_J3_SOC_CPU_Error_PWM_Missing: provided-interface=DiagnosticMonitor
      provided-com-specs:
        operation=SetEventStatus, queue-length=1
        operation=ResetEventStatus, queue-length=1
        operation=PrestoreFreezeFrame, queue-length=1
        operation=ClearPrestoredFreezeFrame, queue-length=1
        operation=ResetEventDebounceStatus, queue-length=1
    provide port EvtInfo_DEM_DTC_J3_SOC_CPU_Error_PWM_Missing: provided-interface=DiagnosticInfo
      provided-com-specs:
        operation=GetEventStatus, queue-length=1
        operation=GetEventFailed, queue-length=1
        operation=GetEventTested, queue-length=1
        operation=GetDTCOfEvent, queue-length=1
        operation=GetFaultDetectionCounter, queue-length=1
        operation=GetEventFreezeFrameData, queue-length=1
        operation=GetEventExtendedDataRecord, queue-length=1
    require port CBStatusEvt_DEM_DTC_J3_SOC_CPU_Error_PWM_Missing_1: required-interface=CallbackEventStatusChange
    provide port Event_DEM_DTC_J3_SOC_Perception_Error: provided-interface=DiagnosticMonitor
      provided-com-specs:
        operation=SetEventStatus, queue-length=1
        operation=ResetEventStatus, queue-length=1
        operation=PrestoreFreezeFrame, queue-length=1
        operation=ClearPrestoredFreezeFrame, queue-length=1
        operation=ResetEventDebounceStatus, queue-length=1
    provide port EvtInfo_DEM_DTC_J3_SOC_Perception_Error: provided-interface=DiagnosticInfo
      provided-com-specs:
        operation=GetEventStatus, queue-length=1
        operation=GetEventFailed, queue-length=1
        operation=GetEventTested, queue-length=1
        operation=GetDTCOfEvent, queue-length=1
        operation=GetFaultDetectionCounter, queue-length=1
        operation=GetEventFreezeFrameData, queue-length=1
        operation=GetEventExtendedDataRecord, queue-length=1
    require port CBStatusEvt_DEM_DTC_J3_SOC_Perception_Error_1: required-interface=CallbackEventStatusChange
    14 x provide port:
      Event_DEM_DTC_ETH_CRC_ERROR: provided-interface=DiagnosticMonitor
        provided-com-specs:
          operation=SetEventStatus, queue-length=1
          operation=ResetEventStatus, queue-length=1
          operation=PrestoreFreezeFrame, queue-length=1
          operation=ClearPrestoredFreezeFrame, queue-length=1
          operation=ResetEventDebounceStatus, queue-length=1
      EvtInfo_DEM_DTC_ETH_CRC_ERROR: provided-interface=DiagnosticInfo
        provided-com-specs:
          operation=GetEventStatus, queue-length=1
          operation=GetEventFailed, queue-length=1
          operation=GetEventTested, queue-length=1
          operation=GetDTCOfEvent, queue-length=1
          operation=GetFaultDetectionCounter, queue-length=1
          operation=GetEventFreezeFrameData, queue-length=1
          operation=GetEventExtendedDataRecord, queue-length=1
      Event_DEM_DTC_ETH_LINK_SIGNAL_WAKE: provided-interface=DiagnosticMonitor
        provided-com-specs:
          operation=SetEventStatus, queue-length=1
          operation=ResetEventStatus, queue-length=1
          operation=PrestoreFreezeFrame, queue-length=1
          operation=ClearPrestoredFreezeFrame, queue-length=1
          operation=ResetEventDebounceStatus, queue-length=1
      EvtInfo_DEM_DTC_ETH_LINK_SIGNAL_WAKE: provided-interface=DiagnosticInfo
        provided-com-specs:
          operation=GetEventStatus, queue-length=1
          operation=GetEventFailed, queue-length=1
          operation=GetEventTested, queue-length=1
          operation=GetDTCOfEvent, queue-length=1
          operation=GetFaultDetectionCounter, queue-length=1
          operation=GetEventFreezeFrameData, queue-length=1
          operation=GetEventExtendedDataRecord, queue-length=1
      Event_DEM_DTC_ETH_CABLE_FAULT: provided-interface=DiagnosticMonitor
        provided-com-specs:
          operation=SetEventStatus, queue-length=1
          operation=ResetEventStatus, queue-length=1
          operation=PrestoreFreezeFrame, queue-length=1
          operation=ClearPrestoredFreezeFrame, queue-length=1
          operation=ResetEventDebounceStatus, queue-length=1
      EvtInfo_DEM_DTC_ETH_CABLE_FAULT: provided-interface=DiagnosticInfo
        provided-com-specs:
          operation=GetEventStatus, queue-length=1
          operation=GetEventFailed, queue-length=1
          operation=GetEventTested, queue-length=1
          operation=GetDTCOfEvent, queue-length=1
          operation=GetFaultDetectionCounter, queue-length=1
          operation=GetEventFreezeFrameData, queue-length=1
          operation=GetEventExtendedDataRecord, queue-length=1
      Event_DEM_DTC_ETH_ICMP_ERROR: provided-interface=DiagnosticMonitor
        provided-com-specs:
          operation=SetEventStatus, queue-length=1
          operation=ResetEventStatus, queue-length=1
          operation=PrestoreFreezeFrame, queue-length=1
          operation=ClearPrestoredFreezeFrame, queue-length=1
          operation=ResetEventDebounceStatus, queue-length=1
      EvtInfo_DEM_DTC_ETH_ICMP_ERROR: provided-interface=DiagnosticInfo
        provided-com-specs:
          operation=GetEventStatus, queue-length=1
          operation=GetEventFailed, queue-length=1
          operation=GetEventTested, queue-length=1
          operation=GetDTCOfEvent, queue-length=1
          operation=GetFaultDetectionCounter, queue-length=1
          operation=GetEventFreezeFrameData, queue-length=1
          operation=GetEventExtendedDataRecord, queue-length=1
      Event_DEM_DTC_SPI_DRIVER_ERROR: provided-interface=DiagnosticMonitor
        provided-com-specs:
          operation=SetEventStatus, queue-length=1
          operation=ResetEventStatus, queue-length=1
          operation=PrestoreFreezeFrame, queue-length=1
          operation=ClearPrestoredFreezeFrame, queue-length=1
          operation=ResetEventDebounceStatus, queue-length=1
      EvtInfo_DEM_DTC_SPI_DRIVER_ERROR: provided-interface=DiagnosticInfo
        provided-com-specs:
          operation=GetEventStatus, queue-length=1
          operation=GetEventFailed, queue-length=1
          operation=GetEventTested, queue-length=1
          operation=GetDTCOfEvent, queue-length=1
          operation=GetFaultDetectionCounter, queue-length=1
          operation=GetEventFreezeFrameData, queue-length=1
          operation=GetEventExtendedDataRecord, queue-length=1
      Event_DEM_DTC_DFLASH_ERROR: provided-interface=DiagnosticMonitor
        provided-com-specs:
          operation=SetEventStatus, queue-length=1
          operation=ResetEventStatus, queue-length=1
          operation=PrestoreFreezeFrame, queue-length=1
          operation=ClearPrestoredFreezeFrame, queue-length=1
          operation=ResetEventDebounceStatus, queue-length=1
      EvtInfo_DEM_DTC_DFLASH_ERROR: provided-interface=DiagnosticInfo
        provided-com-specs:
          operation=GetEventStatus, queue-length=1
          operation=GetEventFailed, queue-length=1
          operation=GetEventTested, queue-length=1
          operation=GetDTCOfEvent, queue-length=1
          operation=GetFaultDetectionCounter, queue-length=1
          operation=GetEventFreezeFrameData, queue-length=1
          operation=GetEventExtendedDataRecord, queue-length=1
      Event_DEM_DTC_BCM_Brake_Lamp_Error: provided-interface=DiagnosticMonitor
        provided-com-specs:
          operation=SetEventStatus, queue-length=1
          operation=ResetEventStatus, queue-length=1
          operation=PrestoreFreezeFrame, queue-length=1
          operation=ClearPrestoredFreezeFrame, queue-length=1
          operation=ResetEventDebounceStatus, queue-length=1
      EvtInfo_DEM_DTC_BCM_Brake_Lamp_Error: provided-interface=DiagnosticInfo
        provided-com-specs:
          operation=GetEventStatus, queue-length=1
          operation=GetEventFailed, queue-length=1
          operation=GetEventTested, queue-length=1
          operation=GetDTCOfEvent, queue-length=1
          operation=GetFaultDetectionCounter, queue-length=1
          operation=GetEventFreezeFrameData, queue-length=1
          operation=GetEventExtendedDataRecord, queue-length=1
    require port CBStatusEvt_DEM_DTC_BCM_Brake_Lamp_Error_1: required-interface=CallbackEventStatusChange
    provide port Event_DEM_DTC_Esp_Ebd_Failr: provided-interface=DiagnosticMonitor
      provided-com-specs:
        operation=SetEventStatus, queue-length=1
        operation=ResetEventStatus, queue-length=1
        operation=PrestoreFreezeFrame, queue-length=1
        operation=ClearPrestoredFreezeFrame, queue-length=1
        operation=ResetEventDebounceStatus, queue-length=1
    provide port EvtInfo_DEM_DTC_Esp_Ebd_Failr: provided-interface=DiagnosticInfo
      provided-com-specs:
        operation=GetEventStatus, queue-length=1
        operation=GetEventFailed, queue-length=1
        operation=GetEventTested, queue-length=1
        operation=GetDTCOfEvent, queue-length=1
        operation=GetFaultDetectionCounter, queue-length=1
        operation=GetEventFreezeFrameData, queue-length=1
        operation=GetEventExtendedDataRecord, queue-length=1
    require port CBStatusEvt_DEM_DTC_Esp_Ebd_Failr_1: required-interface=CallbackEventStatusChange
    provide port Event_DEM_DTC_FR_All_Node_Missing: provided-interface=DiagnosticMonitor
      provided-com-specs:
        operation=SetEventStatus, queue-length=1
        operation=ResetEventStatus, queue-length=1
        operation=PrestoreFreezeFrame, queue-length=1
        operation=ClearPrestoredFreezeFrame, queue-length=1
        operation=ResetEventDebounceStatus, queue-length=1
    provide port EvtInfo_DEM_DTC_FR_All_Node_Missing: provided-interface=DiagnosticInfo
      provided-com-specs:
        operation=GetEventStatus, queue-length=1
        operation=GetEventFailed, queue-length=1
        operation=GetEventTested, queue-length=1
        operation=GetDTCOfEvent, queue-length=1
        operation=GetFaultDetectionCounter, queue-length=1
        operation=GetEventFreezeFrameData, queue-length=1
        operation=GetEventExtendedDataRecord, queue-length=1
    require port CBStatusEvt_DEM_DTC_FR_All_Node_Missing_1: required-interface=CallbackEventStatusChange
    provide port Event_DEM_DTC_ADC_All_Node_Missing: provided-interface=DiagnosticMonitor
      provided-com-specs:
        operation=SetEventStatus, queue-length=1
        operation=ResetEventStatus, queue-length=1
        operation=PrestoreFreezeFrame, queue-length=1
        operation=ClearPrestoredFreezeFrame, queue-length=1
        operation=ResetEventDebounceStatus, queue-length=1
    provide port EvtInfo_DEM_DTC_ADC_All_Node_Missing: provided-interface=DiagnosticInfo
      provided-com-specs:
        operation=GetEventStatus, queue-length=1
        operation=GetEventFailed, queue-length=1
        operation=GetEventTested, queue-length=1
        operation=GetDTCOfEvent, queue-length=1
        operation=GetFaultDetectionCounter, queue-length=1
        operation=GetEventFreezeFrameData, queue-length=1
        operation=GetEventExtendedDataRecord, queue-length=1
    require port CBStatusEvt_DEM_DTC_ADC_All_Node_Missing_1: required-interface=CallbackEventStatusChange
    provide port Event_DEM_DTC_J3_Time_Sync_Error: provided-interface=DiagnosticMonitor
      provided-com-specs:
        operation=SetEventStatus, queue-length=1
        operation=ResetEventStatus, queue-length=1
        operation=PrestoreFreezeFrame, queue-length=1
        operation=ClearPrestoredFreezeFrame, queue-length=1
        operation=ResetEventDebounceStatus, queue-length=1
    provide port EvtInfo_DEM_DTC_J3_Time_Sync_Error: provided-interface=DiagnosticInfo
      provided-com-specs:
        operation=GetEventStatus, queue-length=1
        operation=GetEventFailed, queue-length=1
        operation=GetEventTested, queue-length=1
        operation=GetDTCOfEvent, queue-length=1
        operation=GetFaultDetectionCounter, queue-length=1
        operation=GetEventFreezeFrameData, queue-length=1
        operation=GetEventExtendedDataRecord, queue-length=1
    require port CBStatusEvt_DEM_DTC_J3_Time_Sync_Error_1: required-interface=CallbackEventStatusChange
    7 x provide port:
      EvtInfo_NVM_E_INTEGRITY_FAILED: provided-interface=DiagnosticInfo
        provided-com-specs:
          operation=GetEventStatus, queue-length=1
          operation=GetEventFailed, queue-length=1
          operation=GetEventTested, queue-length=1
          operation=GetDTCOfEvent, queue-length=1
          operation=GetFaultDetectionCounter, queue-length=1
          operation=GetEventFreezeFrameData, queue-length=1
          operation=GetEventExtendedDataRecord, queue-length=1
      EvtInfo_NVM_E_REQ_FAILED: provided-interface=DiagnosticInfo
        provided-com-specs:
          operation=GetEventStatus, queue-length=1
          operation=GetEventFailed, queue-length=1
          operation=GetEventTested, queue-length=1
          operation=GetDTCOfEvent, queue-length=1
          operation=GetFaultDetectionCounter, queue-length=1
          operation=GetEventFreezeFrameData, queue-length=1
          operation=GetEventExtendedDataRecord, queue-length=1
      EvtInfo_NVM_E_WRONG_BLOCK_ID: provided-interface=DiagnosticInfo
        provided-com-specs:
          operation=GetEventStatus, queue-length=1
          operation=GetEventFailed, queue-length=1
          operation=GetEventTested, queue-length=1
          operation=GetDTCOfEvent, queue-length=1
          operation=GetFaultDetectionCounter, queue-length=1
          operation=GetEventFreezeFrameData, queue-length=1
          operation=GetEventExtendedDataRecord, queue-length=1
      EvtInfo_NVM_E_VERIFY_FAILED: provided-interface=DiagnosticInfo
        provided-com-specs:
          operation=GetEventStatus, queue-length=1
          operation=GetEventFailed, queue-length=1
          operation=GetEventTested, queue-length=1
          operation=GetDTCOfEvent, queue-length=1
          operation=GetFaultDetectionCounter, queue-length=1
          operation=GetEventFreezeFrameData, queue-length=1
          operation=GetEventExtendedDataRecord, queue-length=1
      EvtInfo_NVM_E_WRITE_PROTECTED: provided-interface=DiagnosticInfo
        provided-com-specs:
          operation=GetEventStatus, queue-length=1
          operation=GetEventFailed, queue-length=1
          operation=GetEventTested, queue-length=1
          operation=GetDTCOfEvent, queue-length=1
          operation=GetFaultDetectionCounter, queue-length=1
          operation=GetEventFreezeFrameData, queue-length=1
          operation=GetEventExtendedDataRecord, queue-length=1
      Event_DEM_DTC_MCU_TEMP_INITIAL_HIGH: provided-interface=DiagnosticMonitor
        provided-com-specs:
          operation=SetEventStatus, queue-length=1
          operation=ResetEventStatus, queue-length=1
          operation=PrestoreFreezeFrame, queue-length=1
          operation=ClearPrestoredFreezeFrame, queue-length=1
          operation=ResetEventDebounceStatus, queue-length=1
      EvtInfo_DEM_DTC_MCU_TEMP_INITIAL_HIGH: provided-interface=DiagnosticInfo
        provided-com-specs:
          operation=GetEventStatus, queue-length=1
          operation=GetEventFailed, queue-length=1
          operation=GetEventTested, queue-length=1
          operation=GetDTCOfEvent, queue-length=1
          operation=GetFaultDetectionCounter, queue-length=1
          operation=GetEventFreezeFrameData, queue-length=1
          operation=GetEventExtendedDataRecord, queue-length=1
    require port CBStatusEvt_DEM_DTC_MCU_TEMP_INITIAL_HIGH_1: required-interface=CallbackEventStatusChange
    provide port Event_DEM_DTC_ESP_Message_Alive_Counter_Error_100ms: provided-interface=DiagnosticMonitor
      provided-com-specs:
        operation=SetEventStatus, queue-length=1
        operation=ResetEventStatus, queue-length=1
        operation=PrestoreFreezeFrame, queue-length=1
        operation=ClearPrestoredFreezeFrame, queue-length=1
        operation=ResetEventDebounceStatus, queue-length=1
    provide port EvtInfo_DEM_DTC_ESP_Message_Alive_Counter_Error_100ms: provided-interface=DiagnosticInfo
      provided-com-specs:
        operation=GetEventStatus, queue-length=1
        operation=GetEventFailed, queue-length=1
        operation=GetEventTested, queue-length=1
        operation=GetDTCOfEvent, queue-length=1
        operation=GetFaultDetectionCounter, queue-length=1
        operation=GetEventFreezeFrameData, queue-length=1
        operation=GetEventExtendedDataRecord, queue-length=1
    require port CBStatusEvt_DEM_DTC_ESP_Message_Alive_Counter_Error_100ms_1: required-interface=CallbackEventStatusChange
    12 x provide port:
      EvtInfo_WDG_E_DISABLE_REJECTED: provided-interface=DiagnosticInfo
        provided-com-specs:
          operation=GetEventStatus, queue-length=1
          operation=GetEventFailed, queue-length=1
          operation=GetEventTested, queue-length=1
          operation=GetDTCOfEvent, queue-length=1
          operation=GetFaultDetectionCounter, queue-length=1
          operation=GetEventFreezeFrameData, queue-length=1
          operation=GetEventExtendedDataRecord, queue-length=1
      EvtInfo_WDG_E_MODE_FAILED: provided-interface=DiagnosticInfo
        provided-com-specs:
          operation=GetEventStatus, queue-length=1
          operation=GetEventFailed, queue-length=1
          operation=GetEventTested, queue-length=1
          operation=GetDTCOfEvent, queue-length=1
          operation=GetFaultDetectionCounter, queue-length=1
          operation=GetEventFreezeFrameData, queue-length=1
          operation=GetEventExtendedDataRecord, queue-length=1
      EvtInfo_SmuActivateRunStateFailureNotification: provided-interface=DiagnosticInfo
        provided-com-specs:
          operation=GetEventStatus, queue-length=1
          operation=GetEventFailed, queue-length=1
          operation=GetEventTested, queue-length=1
          operation=GetDTCOfEvent, queue-length=1
          operation=GetFaultDetectionCounter, queue-length=1
          operation=GetEventFreezeFrameData, queue-length=1
          operation=GetEventExtendedDataRecord, queue-length=1
      EvtInfo_SmuClearAlarmStatusFailureNotification: provided-interface=DiagnosticInfo
        provided-com-specs:
          operation=GetEventStatus, queue-length=1
          operation=GetEventFailed, queue-length=1
          operation=GetEventTested, queue-length=1
          operation=GetDTCOfEvent, queue-length=1
          operation=GetFaultDetectionCounter, queue-length=1
          operation=GetEventFreezeFrameData, queue-length=1
          operation=GetEventExtendedDataRecord, queue-length=1
      EvtInfo_SmuReleaseFSPFailureNotification: provided-interface=DiagnosticInfo
        provided-com-specs:
          operation=GetEventStatus, queue-length=1
          operation=GetEventFailed, queue-length=1
          operation=GetEventTested, queue-length=1
          operation=GetDTCOfEvent, queue-length=1
          operation=GetFaultDetectionCounter, queue-length=1
          operation=GetEventFreezeFrameData, queue-length=1
          operation=GetEventExtendedDataRecord, queue-length=1
      EvtInfo_SmuCoreAliveFailureNotification: provided-interface=DiagnosticInfo
        provided-com-specs:
          operation=GetEventStatus, queue-length=1
          operation=GetEventFailed, queue-length=1
          operation=GetEventTested, queue-length=1
          operation=GetDTCOfEvent, queue-length=1
          operation=GetFaultDetectionCounter, queue-length=1
          operation=GetEventFreezeFrameData, queue-length=1
          operation=GetEventExtendedDataRecord, queue-length=1
      EvtInfo_SmuRTStopFailureNotification: provided-interface=DiagnosticInfo
        provided-com-specs:
          operation=GetEventStatus, queue-length=1
          operation=GetEventFailed, queue-length=1
          operation=GetEventTested, queue-length=1
          operation=GetDTCOfEvent, queue-length=1
          operation=GetFaultDetectionCounter, queue-length=1
          operation=GetEventFreezeFrameData, queue-length=1
          operation=GetEventExtendedDataRecord, queue-length=1
      EvtInfo_SmuActivatePESFailureNotification: provided-interface=DiagnosticInfo
        provided-com-specs:
          operation=GetEventStatus, queue-length=1
          operation=GetEventFailed, queue-length=1
          operation=GetEventTested, queue-length=1
          operation=GetDTCOfEvent, queue-length=1
          operation=GetFaultDetectionCounter, queue-length=1
          operation=GetEventFreezeFrameData, queue-length=1
          operation=GetEventExtendedDataRecord, queue-length=1
      EvtInfo_SmuActivateFSPFailureNotification: provided-interface=DiagnosticInfo
        provided-com-specs:
          operation=GetEventStatus, queue-length=1
          operation=GetEventFailed, queue-length=1
          operation=GetEventTested, queue-length=1
          operation=GetDTCOfEvent, queue-length=1
          operation=GetFaultDetectionCounter, queue-length=1
          operation=GetEventFreezeFrameData, queue-length=1
          operation=GetEventExtendedDataRecord, queue-length=1
      EvtInfo_SmuSetAlarmStatusFailureNotification: provided-interface=DiagnosticInfo
        provided-com-specs:
          operation=GetEventStatus, queue-length=1
          operation=GetEventFailed, queue-length=1
          operation=GetEventTested, queue-length=1
          operation=GetDTCOfEvent, queue-length=1
          operation=GetFaultDetectionCounter, queue-length=1
          operation=GetEventFreezeFrameData, queue-length=1
          operation=GetEventExtendedDataRecord, queue-length=1
      EvtInfo_SmuSffFailureNotification: provided-interface=DiagnosticInfo
        provided-com-specs:
          operation=GetEventStatus, queue-length=1
          operation=GetEventFailed, queue-length=1
          operation=GetEventTested, queue-length=1
          operation=GetDTCOfEvent, queue-length=1
          operation=GetFaultDetectionCounter, queue-length=1
          operation=GetEventFreezeFrameData, queue-length=1
          operation=GetEventExtendedDataRecord, queue-length=1
      GeneralEvtInfo: provided-interface=GeneralDiagnosticInfo
        provided-com-specs:
          operation=GetEventStatus, queue-length=1
          operation=GetEventFailed, queue-length=1
          operation=GetEventTested, queue-length=1
          operation=GetDTCOfEvent, queue-length=1
          operation=GetFaultDetectionCounter, queue-length=1
          operation=GetEventFreezeFrameData, queue-length=1
          operation=GetEventExtendedDataRecord, queue-length=1
    require port GeneralCBStatusEvt: required-interface=GeneralCallbackEventStatusChange
    10 x provide port:
      OpCycle_DEM_OPCYC_POWER: provided-com-specs=[{operation=SetOperationCycleState, queue-length=1}, {operation=SetCycleQualified, queue-length=1}], provided-interface=OperationCycle
      OpCycle_DEM_OPCYC_IGN: provided-com-specs=[{operation=SetOperationCycleState, queue-length=1}, {operation=SetCycleQualified, queue-length=1}], provided-interface=OperationCycle
      EnableCond_CONDITION_Voltage_Normal: server-com-spec{operation=SetEnableCondition, queue-length=1}, provided-interface=EnableCondition
      EnableCond_CONDITION_PowerON_3000ms: server-com-spec{operation=SetEnableCondition, queue-length=1}, provided-interface=EnableCondition
      EnableCond_CONDITION_Voltage_InRange: server-com-spec{operation=SetEnableCondition, queue-length=1}, provided-interface=EnableCondition
      EnableCond_CONDITION_NO_BUSOFF_PublicCAN: server-com-spec{operation=SetEnableCondition, queue-length=1}, provided-interface=EnableCondition
      EnableCond_CONDITION_NO_BUSOFF_PrivateCAN: server-com-spec{operation=SetEnableCondition, queue-length=1}, provided-interface=EnableCondition
      EnableCond_CONDITION_BcmPwrStsFbON: server-com-spec{operation=SetEnableCondition, queue-length=1}, provided-interface=EnableCondition
      EnableCond_CONDITION_EspVehSpd: server-com-spec{operation=SetEnableCondition, queue-length=1}, provided-interface=EnableCondition
      OverflowIndPrimaryMemory: provided-interface=EvMemOverflowIndication
        provided-com-specs:
          operation=GetEventMemoryOverflow, queue-length=1
          operation=GetNumberOfEventMemoryEntries, queue-length=1
    10 x require port:
      CBReadData_DemDataElementClass_Odometer: required-interface=CSDataServices_DemDataElementClass_Odometer
      CBReadData_DemDataElementClass_Voltage: required-interface=CSDataServices_DemDataElementClass_Voltage
      CBReadData_DemDataElementClass_VehicleSpeed: required-interface=CSDataServices_DemDataElementClass_VehicleSpeed
      CBReadData_DemDataElementClass_LocalTime: required-interface=CSDataServices_DemDataElementClass_LocalTime
      CBReadData_DemDataElementClass_ECUTemperature: required-interface=CSDataServices_DemDataElementClass_ECUTemperature
      CBReadData_DemDataElementClass_Yawrate: required-interface=CSDataServices_DemDataElementClass_Yawrate
      CBReadData_DemDataElementClass_EngineSpeed: required-interface=CSDataServices_DemDataElementClass_EngineSpeed
      CBReadData_DemDataElementClass_GearPosition: required-interface=CSDataServices_DemDataElementClass_GearPosition
      CBReadData_DemDataElementClass_SteeringAngle: required-interface=CSDataServices_DemDataElementClass_SteeringAngle
      CBReadData_DemDataElementClass_Extended_SystemKernelErrMap: required-interface=CSDataServices_DemDataElementClass_Extended_SystemKernelErrMap
    behavior DemIntBeh: handle-termination-and-restart=NO-SUPPORT, included-data-type-set=data-type=[Dem_EventStatusType, Dem_InitMonitorReasonType, Dem_IndicatorStatusType, Dem_EnableConditionType]
      1413 x operation invoked event:
        EV_GetEventStatus_EvtMCU_E_CLOCK_FAILURE: start-on-event=RE_GetEventStatus, operation=EvtInfo_MCU_E_CLOCK_FAILURE.GetEventStatus
        EV_GetEventFailed_EvtMCU_E_CLOCK_FAILURE: start-on-event=RE_GetEventFailed, operation=EvtInfo_MCU_E_CLOCK_FAILURE.GetEventFailed
        EV_GetEventTested_EvtMCU_E_CLOCK_FAILURE: start-on-event=RE_GetEventTested, operation=EvtInfo_MCU_E_CLOCK_FAILURE.GetEventTested
        EV_GetDTCOfEvent_EvtMCU_E_CLOCK_FAILURE: start-on-event=RE_GetDTCOfEvent, operation=EvtInfo_MCU_E_CLOCK_FAILURE.GetDTCOfEvent
        EV_GetFDC_EvtMCU_E_CLOCK_FAILURE: start-on-event=RE_GetFaultDetectionCounter, operation=EvtInfo_MCU_E_CLOCK_FAILURE.GetFaultDetectionCounter
        EV_GetEventFF_EvtMCU_E_CLOCK_FAILURE: start-on-event=RE_GetEventFreezeFrameData, operation=EvtInfo_MCU_E_CLOCK_FAILURE.GetEventFreezeFrameData
        EV_GetEventEDR_EvtMCU_E_CLOCK_FAILURE: start-on-event=RE_GetEventExtendedDataRecord, operation=EvtInfo_MCU_E_CLOCK_FAILURE.GetEventExtendedDataRecord
        EV_GetEventStatus_EvtMCU_E_OSC_FAILURE: start-on-event=RE_GetEventStatus, operation=EvtInfo_MCU_E_OSC_FAILURE.GetEventStatus
        EV_GetEventFailed_EvtMCU_E_OSC_FAILURE: start-on-event=RE_GetEventFailed, operation=EvtInfo_MCU_E_OSC_FAILURE.GetEventFailed
        EV_GetEventTested_EvtMCU_E_OSC_FAILURE: start-on-event=RE_GetEventTested, operation=EvtInfo_MCU_E_OSC_FAILURE.GetEventTested
        EV_GetDTCOfEvent_EvtMCU_E_OSC_FAILURE: start-on-event=RE_GetDTCOfEvent, operation=EvtInfo_MCU_E_OSC_FAILURE.GetDTCOfEvent
        EV_GetFDC_EvtMCU_E_OSC_FAILURE: start-on-event=RE_GetFaultDetectionCounter, operation=EvtInfo_MCU_E_OSC_FAILURE.GetFaultDetectionCounter
        EV_GetEventFF_EvtMCU_E_OSC_FAILURE: start-on-event=RE_GetEventFreezeFrameData, operation=EvtInfo_MCU_E_OSC_FAILURE.GetEventFreezeFrameData
        EV_GetEventEDR_EvtMCU_E_OSC_FAILURE: start-on-event=RE_GetEventExtendedDataRecord, operation=EvtInfo_MCU_E_OSC_FAILURE.GetEventExtendedDataRecord
        EV_GetEventStatus_EvtMCU_E_SYSTEM_PLL_TIMEOUT_ERR: start-on-event=RE_GetEventStatus, operation=EvtInfo_MCU_E_SYSTEM_PLL_TIMEOUT_ERR.GetEventStatus
        EV_GetEventFailed_EvtMCU_E_SYSTEM_PLL_TIMEOUT_ERR: start-on-event=RE_GetEventFailed, operation=EvtInfo_MCU_E_SYSTEM_PLL_TIMEOUT_ERR.GetEventFailed
        EV_GetEventTested_EvtMCU_E_SYSTEM_PLL_TIMEOUT_ERR: start-on-event=RE_GetEventTested, operation=EvtInfo_MCU_E_SYSTEM_PLL_TIMEOUT_ERR.GetEventTested
        EV_GetDTCOfEvent_EvtMCU_E_SYSTEM_PLL_TIMEOUT_ERR: start-on-event=RE_GetDTCOfEvent, operation=EvtInfo_MCU_E_SYSTEM_PLL_TIMEOUT_ERR.GetDTCOfEvent
        EV_GetFDC_EvtMCU_E_SYSTEM_PLL_TIMEOUT_ERR: start-on-event=RE_GetFaultDetectionCounter, operation=EvtInfo_MCU_E_SYSTEM_PLL_TIMEOUT_ERR.GetFaultDetectionCounter
        EV_GetEventFF_EvtMCU_E_SYSTEM_PLL_TIMEOUT_ERR: start-on-event=RE_GetEventFreezeFrameData, operation=EvtInfo_MCU_E_SYSTEM_PLL_TIMEOUT_ERR.GetEventFreezeFrameData
        EV_GetEventEDR_EvtMCU_E_SYSTEM_PLL_TIMEOUT_ERR: start-on-event=RE_GetEventExtendedDataRecord, operation=EvtInfo_MCU_E_SYSTEM_PLL_TIMEOUT_ERR.GetEventExtendedDataRecord
        EV_GetEventStatus_EvtMCU_E_PERIPHERAL_PLL_TIMEOUT_ERR: start-on-event=RE_GetEventStatus, operation=EvtInfo_MCU_E_PERIPHERAL_PLL_TIMEOUT_ERR.GetEventStatus
        EV_GetEventFailed_EvtMCU_E_PERIPHERAL_PLL_TIMEOUT_ERR: start-on-event=RE_GetEventFailed, operation=EvtInfo_MCU_E_PERIPHERAL_PLL_TIMEOUT_ERR.GetEventFailed
        EV_GetEventTested_EvtMCU_E_PERIPHERAL_PLL_TIMEOUT_ERR: start-on-event=RE_GetEventTested, operation=EvtInfo_MCU_E_PERIPHERAL_PLL_TIMEOUT_ERR.GetEventTested
        EV_GetDTCOfEvent_EvtMCU_E_PERIPHERAL_PLL_TIMEOUT_ERR: start-on-event=RE_GetDTCOfEvent, operation=EvtInfo_MCU_E_PERIPHERAL_PLL_TIMEOUT_ERR.GetDTCOfEvent
        EV_GetFDC_EvtMCU_E_PERIPHERAL_PLL_TIMEOUT_ERR: start-on-event=RE_GetFaultDetectionCounter, operation=EvtInfo_MCU_E_PERIPHERAL_PLL_TIMEOUT_ERR.GetFaultDetectionCounter
        EV_GetEventFF_EvtMCU_E_PERIPHERAL_PLL_TIMEOUT_ERR: start-on-event=RE_GetEventFreezeFrameData, operation=EvtInfo_MCU_E_PERIPHERAL_PLL_TIMEOUT_ERR.GetEventFreezeFrameData
        EV_GetEventEDR_EvtMCU_E_PERIPHERAL_PLL_TIMEOUT_ERR: start-on-event=RE_GetEventExtendedDataRecord, operation=EvtInfo_MCU_E_PERIPHERAL_PLL_TIMEOUT_ERR.GetEventExtendedDataRecord
        EV_GetEventStatus_EvtMCU_E_SYSTEM_PLL_LOCK_LOSS: start-on-event=RE_GetEventStatus, operation=EvtInfo_MCU_E_SYSTEM_PLL_LOCK_LOSS.GetEventStatus
        EV_GetEventFailed_EvtMCU_E_SYSTEM_PLL_LOCK_LOSS: start-on-event=RE_GetEventFailed, operation=EvtInfo_MCU_E_SYSTEM_PLL_LOCK_LOSS.GetEventFailed
        EV_GetEventTested_EvtMCU_E_SYSTEM_PLL_LOCK_LOSS: start-on-event=RE_GetEventTested, operation=EvtInfo_MCU_E_SYSTEM_PLL_LOCK_LOSS.GetEventTested
        EV_GetDTCOfEvent_EvtMCU_E_SYSTEM_PLL_LOCK_LOSS: start-on-event=RE_GetDTCOfEvent, operation=EvtInfo_MCU_E_SYSTEM_PLL_LOCK_LOSS.GetDTCOfEvent
        EV_GetFDC_EvtMCU_E_SYSTEM_PLL_LOCK_LOSS: start-on-event=RE_GetFaultDetectionCounter, operation=EvtInfo_MCU_E_SYSTEM_PLL_LOCK_LOSS.GetFaultDetectionCounter
        EV_GetEventFF_EvtMCU_E_SYSTEM_PLL_LOCK_LOSS: start-on-event=RE_GetEventFreezeFrameData, operation=EvtInfo_MCU_E_SYSTEM_PLL_LOCK_LOSS.GetEventFreezeFrameData
        EV_GetEventEDR_EvtMCU_E_SYSTEM_PLL_LOCK_LOSS: start-on-event=RE_GetEventExtendedDataRecord, operation=EvtInfo_MCU_E_SYSTEM_PLL_LOCK_LOSS.GetEventExtendedDataRecord
        EV_GetEventStatus_EvtMCU_E_PERIPHERAL_PLL_LOCK_LOSS: start-on-event=RE_GetEventStatus, operation=EvtInfo_MCU_E_PERIPHERAL_PLL_LOCK_LOSS.GetEventStatus
        EV_GetEventFailed_EvtMCU_E_PERIPHERAL_PLL_LOCK_LOSS: start-on-event=RE_GetEventFailed, operation=EvtInfo_MCU_E_PERIPHERAL_PLL_LOCK_LOSS.GetEventFailed
        EV_GetEventTested_EvtMCU_E_PERIPHERAL_PLL_LOCK_LOSS: start-on-event=RE_GetEventTested, operation=EvtInfo_MCU_E_PERIPHERAL_PLL_LOCK_LOSS.GetEventTested
        EV_GetDTCOfEvent_EvtMCU_E_PERIPHERAL_PLL_LOCK_LOSS: start-on-event=RE_GetDTCOfEvent, operation=EvtInfo_MCU_E_PERIPHERAL_PLL_LOCK_LOSS.GetDTCOfEvent
        EV_GetFDC_EvtMCU_E_PERIPHERAL_PLL_LOCK_LOSS: start-on-event=RE_GetFaultDetectionCounter, operation=EvtInfo_MCU_E_PERIPHERAL_PLL_LOCK_LOSS.GetFaultDetectionCounter
        EV_GetEventFF_EvtMCU_E_PERIPHERAL_PLL_LOCK_LOSS: start-on-event=RE_GetEventFreezeFrameData, operation=EvtInfo_MCU_E_PERIPHERAL_PLL_LOCK_LOSS.GetEventFreezeFrameData
        EV_GetEventEDR_EvtMCU_E_PERIPHERAL_PLL_LOCK_LOSS: start-on-event=RE_GetEventExtendedDataRecord, operation=EvtInfo_MCU_E_PERIPHERAL_PLL_LOCK_LOSS.GetEventExtendedDataRecord
        EV_GetEventStatus_EvtMCU_E_GTM_CLC_ENABLE_ERR: start-on-event=RE_GetEventStatus, operation=EvtInfo_MCU_E_GTM_CLC_ENABLE_ERR.GetEventStatus
        EV_GetEventFailed_EvtMCU_E_GTM_CLC_ENABLE_ERR: start-on-event=RE_GetEventFailed, operation=EvtInfo_MCU_E_GTM_CLC_ENABLE_ERR.GetEventFailed
        EV_GetEventTested_EvtMCU_E_GTM_CLC_ENABLE_ERR: start-on-event=RE_GetEventTested, operation=EvtInfo_MCU_E_GTM_CLC_ENABLE_ERR.GetEventTested
        EV_GetDTCOfEvent_EvtMCU_E_GTM_CLC_ENABLE_ERR: start-on-event=RE_GetDTCOfEvent, operation=EvtInfo_MCU_E_GTM_CLC_ENABLE_ERR.GetDTCOfEvent
        EV_GetFDC_EvtMCU_E_GTM_CLC_ENABLE_ERR: start-on-event=RE_GetFaultDetectionCounter, operation=EvtInfo_MCU_E_GTM_CLC_ENABLE_ERR.GetFaultDetectionCounter
        EV_GetEventFF_EvtMCU_E_GTM_CLC_ENABLE_ERR: start-on-event=RE_GetEventFreezeFrameData, operation=EvtInfo_MCU_E_GTM_CLC_ENABLE_ERR.GetEventFreezeFrameData
        EV_GetEventEDR_EvtMCU_E_GTM_CLC_ENABLE_ERR: start-on-event=RE_GetEventExtendedDataRecord, operation=EvtInfo_MCU_E_GTM_CLC_ENABLE_ERR.GetEventExtendedDataRecord
        EV_GetEventStatus_EvtMCU_E_GTM_CLC_DISABLE_ERR: start-on-event=RE_GetEventStatus, operation=EvtInfo_MCU_E_GTM_CLC_DISABLE_ERR.GetEventStatus
        EV_GetEventFailed_EvtMCU_E_GTM_CLC_DISABLE_ERR: start-on-event=RE_GetEventFailed, operation=EvtInfo_MCU_E_GTM_CLC_DISABLE_ERR.GetEventFailed
        EV_GetEventTested_EvtMCU_E_GTM_CLC_DISABLE_ERR: start-on-event=RE_GetEventTested, operation=EvtInfo_MCU_E_GTM_CLC_DISABLE_ERR.GetEventTested
        EV_GetDTCOfEvent_EvtMCU_E_GTM_CLC_DISABLE_ERR: start-on-event=RE_GetDTCOfEvent, operation=EvtInfo_MCU_E_GTM_CLC_DISABLE_ERR.GetDTCOfEvent
        EV_GetFDC_EvtMCU_E_GTM_CLC_DISABLE_ERR: start-on-event=RE_GetFaultDetectionCounter, operation=EvtInfo_MCU_E_GTM_CLC_DISABLE_ERR.GetFaultDetectionCounter
        EV_GetEventFF_EvtMCU_E_GTM_CLC_DISABLE_ERR: start-on-event=RE_GetEventFreezeFrameData, operation=EvtInfo_MCU_E_GTM_CLC_DISABLE_ERR.GetEventFreezeFrameData
        EV_GetEventEDR_EvtMCU_E_GTM_CLC_DISABLE_ERR: start-on-event=RE_GetEventExtendedDataRecord, operation=EvtInfo_MCU_E_GTM_CLC_DISABLE_ERR.GetEventExtendedDataRecord
        EV_GetEventStatus_EvtMCU_E_CONVCTRL_CLC_ENABLE_ERR: start-on-event=RE_GetEventStatus, operation=EvtInfo_MCU_E_CONVCTRL_CLC_ENABLE_ERR.GetEventStatus
        EV_GetEventFailed_EvtMCU_E_CONVCTRL_CLC_ENABLE_ERR: start-on-event=RE_GetEventFailed, operation=EvtInfo_MCU_E_CONVCTRL_CLC_ENABLE_ERR.GetEventFailed
        EV_GetEventTested_EvtMCU_E_CONVCTRL_CLC_ENABLE_ERR: start-on-event=RE_GetEventTested, operation=EvtInfo_MCU_E_CONVCTRL_CLC_ENABLE_ERR.GetEventTested
        EV_GetDTCOfEvent_EvtMCU_E_CONVCTRL_CLC_ENABLE_ERR: start-on-event=RE_GetDTCOfEvent, operation=EvtInfo_MCU_E_CONVCTRL_CLC_ENABLE_ERR.GetDTCOfEvent
        EV_GetFDC_EvtMCU_E_CONVCTRL_CLC_ENABLE_ERR: start-on-event=RE_GetFaultDetectionCounter, operation=EvtInfo_MCU_E_CONVCTRL_CLC_ENABLE_ERR.GetFaultDetectionCounter
        EV_GetEventFF_EvtMCU_E_CONVCTRL_CLC_ENABLE_ERR: start-on-event=RE_GetEventFreezeFrameData, operation=EvtInfo_MCU_E_CONVCTRL_CLC_ENABLE_ERR.GetEventFreezeFrameData
        EV_GetEventEDR_EvtMCU_E_CONVCTRL_CLC_ENABLE_ERR: start-on-event=RE_GetEventExtendedDataRecord, operation=EvtInfo_MCU_E_CONVCTRL_CLC_ENABLE_ERR.GetEventExtendedDataRecord
        EV_GetEventStatus_EvtMCU_E_CONVCTRL_CLC_DISABLE_ERR: start-on-event=RE_GetEventStatus, operation=EvtInfo_MCU_E_CONVCTRL_CLC_DISABLE_ERR.GetEventStatus
        EV_GetEventFailed_EvtMCU_E_CONVCTRL_CLC_DISABLE_ERR: start-on-event=RE_GetEventFailed, operation=EvtInfo_MCU_E_CONVCTRL_CLC_DISABLE_ERR.GetEventFailed
        EV_GetEventTested_EvtMCU_E_CONVCTRL_CLC_DISABLE_ERR: start-on-event=RE_GetEventTested, operation=EvtInfo_MCU_E_CONVCTRL_CLC_DISABLE_ERR.GetEventTested
        EV_GetDTCOfEvent_EvtMCU_E_CONVCTRL_CLC_DISABLE_ERR: start-on-event=RE_GetDTCOfEvent, operation=EvtInfo_MCU_E_CONVCTRL_CLC_DISABLE_ERR.GetDTCOfEvent
        EV_GetFDC_EvtMCU_E_CONVCTRL_CLC_DISABLE_ERR: start-on-event=RE_GetFaultDetectionCounter, operation=EvtInfo_MCU_E_CONVCTRL_CLC_DISABLE_ERR.GetFaultDetectionCounter
        EV_GetEventFF_EvtMCU_E_CONVCTRL_CLC_DISABLE_ERR: start-on-event=RE_GetEventFreezeFrameData, operation=EvtInfo_MCU_E_CONVCTRL_CLC_DISABLE_ERR.GetEventFreezeFrameData
        EV_GetEventEDR_EvtMCU_E_CONVCTRL_CLC_DISABLE_ERR: start-on-event=RE_GetEventExtendedDataRecord, operation=EvtInfo_MCU_E_CONVCTRL_CLC_DISABLE_ERR.GetEventExtendedDataRecord
        EV_GetEventStatus_EvtMCU_E_CCUCON_UPDATE_ERR: start-on-event=RE_GetEventStatus, operation=EvtInfo_MCU_E_CCUCON_UPDATE_ERR.GetEventStatus
        EV_GetEventFailed_EvtMCU_E_CCUCON_UPDATE_ERR: start-on-event=RE_GetEventFailed, operation=EvtInfo_MCU_E_CCUCON_UPDATE_ERR.GetEventFailed
        EV_GetEventTested_EvtMCU_E_CCUCON_UPDATE_ERR: start-on-event=RE_GetEventTested, operation=EvtInfo_MCU_E_CCUCON_UPDATE_ERR.GetEventTested
        EV_GetDTCOfEvent_EvtMCU_E_CCUCON_UPDATE_ERR: start-on-event=RE_GetDTCOfEvent, operation=EvtInfo_MCU_E_CCUCON_UPDATE_ERR.GetDTCOfEvent
        EV_GetFDC_EvtMCU_E_CCUCON_UPDATE_ERR: start-on-event=RE_GetFaultDetectionCounter, operation=EvtInfo_MCU_E_CCUCON_UPDATE_ERR.GetFaultDetectionCounter
        EV_GetEventFF_EvtMCU_E_CCUCON_UPDATE_ERR: start-on-event=RE_GetEventFreezeFrameData, operation=EvtInfo_MCU_E_CCUCON_UPDATE_ERR.GetEventFreezeFrameData
        EV_GetEventEDR_EvtMCU_E_CCUCON_UPDATE_ERR: start-on-event=RE_GetEventExtendedDataRecord, operation=EvtInfo_MCU_E_CCUCON_UPDATE_ERR.GetEventExtendedDataRecord
        EV_GetEventStatus_EvtMCU_E_CCU6_CLC_ENABLE_ERR: start-on-event=RE_GetEventStatus, operation=EvtInfo_MCU_E_CCU6_CLC_ENABLE_ERR.GetEventStatus
        EV_GetEventFailed_EvtMCU_E_CCU6_CLC_ENABLE_ERR: start-on-event=RE_GetEventFailed, operation=EvtInfo_MCU_E_CCU6_CLC_ENABLE_ERR.GetEventFailed
        EV_GetEventTested_EvtMCU_E_CCU6_CLC_ENABLE_ERR: start-on-event=RE_GetEventTested, operation=EvtInfo_MCU_E_CCU6_CLC_ENABLE_ERR.GetEventTested
        EV_GetDTCOfEvent_EvtMCU_E_CCU6_CLC_ENABLE_ERR: start-on-event=RE_GetDTCOfEvent, operation=EvtInfo_MCU_E_CCU6_CLC_ENABLE_ERR.GetDTCOfEvent
        EV_GetFDC_EvtMCU_E_CCU6_CLC_ENABLE_ERR: start-on-event=RE_GetFaultDetectionCounter, operation=EvtInfo_MCU_E_CCU6_CLC_ENABLE_ERR.GetFaultDetectionCounter
        EV_GetEventFF_EvtMCU_E_CCU6_CLC_ENABLE_ERR: start-on-event=RE_GetEventFreezeFrameData, operation=EvtInfo_MCU_E_CCU6_CLC_ENABLE_ERR.GetEventFreezeFrameData
        EV_GetEventEDR_EvtMCU_E_CCU6_CLC_ENABLE_ERR: start-on-event=RE_GetEventExtendedDataRecord, operation=EvtInfo_MCU_E_CCU6_CLC_ENABLE_ERR.GetEventExtendedDataRecord
        EV_GetEventStatus_EvtMCU_E_CCU6_CLC_DISABLE_ERR: start-on-event=RE_GetEventStatus, operation=EvtInfo_MCU_E_CCU6_CLC_DISABLE_ERR.GetEventStatus
        EV_GetEventFailed_EvtMCU_E_CCU6_CLC_DISABLE_ERR: start-on-event=RE_GetEventFailed, operation=EvtInfo_MCU_E_CCU6_CLC_DISABLE_ERR.GetEventFailed
        EV_GetEventTested_EvtMCU_E_CCU6_CLC_DISABLE_ERR: start-on-event=RE_GetEventTested, operation=EvtInfo_MCU_E_CCU6_CLC_DISABLE_ERR.GetEventTested
        EV_GetDTCOfEvent_EvtMCU_E_CCU6_CLC_DISABLE_ERR: start-on-event=RE_GetDTCOfEvent, operation=EvtInfo_MCU_E_CCU6_CLC_DISABLE_ERR.GetDTCOfEvent
        EV_GetFDC_EvtMCU_E_CCU6_CLC_DISABLE_ERR: start-on-event=RE_GetFaultDetectionCounter, operation=EvtInfo_MCU_E_CCU6_CLC_DISABLE_ERR.GetFaultDetectionCounter
        EV_GetEventFF_EvtMCU_E_CCU6_CLC_DISABLE_ERR: start-on-event=RE_GetEventFreezeFrameData, operation=EvtInfo_MCU_E_CCU6_CLC_DISABLE_ERR.GetEventFreezeFrameData
        EV_GetEventEDR_EvtMCU_E_CCU6_CLC_DISABLE_ERR: start-on-event=RE_GetEventExtendedDataRecord, operation=EvtInfo_MCU_E_CCU6_CLC_DISABLE_ERR.GetEventExtendedDataRecord
        EV_GetEventStatus_EvtMCU_E_GPT12_CLC_ENABLE_ERR: start-on-event=RE_GetEventStatus, operation=EvtInfo_MCU_E_GPT12_CLC_ENABLE_ERR.GetEventStatus
        EV_GetEventFailed_EvtMCU_E_GPT12_CLC_ENABLE_ERR: start-on-event=RE_GetEventFailed, operation=EvtInfo_MCU_E_GPT12_CLC_ENABLE_ERR.GetEventFailed
        EV_GetEventTested_EvtMCU_E_GPT12_CLC_ENABLE_ERR: start-on-event=RE_GetEventTested, operation=EvtInfo_MCU_E_GPT12_CLC_ENABLE_ERR.GetEventTested
        EV_GetDTCOfEvent_EvtMCU_E_GPT12_CLC_ENABLE_ERR: start-on-event=RE_GetDTCOfEvent, operation=EvtInfo_MCU_E_GPT12_CLC_ENABLE_ERR.GetDTCOfEvent
        EV_GetFDC_EvtMCU_E_GPT12_CLC_ENABLE_ERR: start-on-event=RE_GetFaultDetectionCounter, operation=EvtInfo_MCU_E_GPT12_CLC_ENABLE_ERR.GetFaultDetectionCounter
        EV_GetEventFF_EvtMCU_E_GPT12_CLC_ENABLE_ERR: start-on-event=RE_GetEventFreezeFrameData, operation=EvtInfo_MCU_E_GPT12_CLC_ENABLE_ERR.GetEventFreezeFrameData
        EV_GetEventEDR_EvtMCU_E_GPT12_CLC_ENABLE_ERR: start-on-event=RE_GetEventExtendedDataRecord, operation=EvtInfo_MCU_E_GPT12_CLC_ENABLE_ERR.GetEventExtendedDataRecord
        EV_GetEventStatus_EvtMCU_E_GPT12_CLC_DISABLE_ERR: start-on-event=RE_GetEventStatus, operation=EvtInfo_MCU_E_GPT12_CLC_DISABLE_ERR.GetEventStatus
        EV_GetEventFailed_EvtMCU_E_GPT12_CLC_DISABLE_ERR: start-on-event=RE_GetEventFailed, operation=EvtInfo_MCU_E_GPT12_CLC_DISABLE_ERR.GetEventFailed
        EV_GetEventTested_EvtMCU_E_GPT12_CLC_DISABLE_ERR: start-on-event=RE_GetEventTested, operation=EvtInfo_MCU_E_GPT12_CLC_DISABLE_ERR.GetEventTested
        EV_GetDTCOfEvent_EvtMCU_E_GPT12_CLC_DISABLE_ERR: start-on-event=RE_GetDTCOfEvent, operation=EvtInfo_MCU_E_GPT12_CLC_DISABLE_ERR.GetDTCOfEvent
        EV_GetFDC_EvtMCU_E_GPT12_CLC_DISABLE_ERR: start-on-event=RE_GetFaultDetectionCounter, operation=EvtInfo_MCU_E_GPT12_CLC_DISABLE_ERR.GetFaultDetectionCounter
        EV_GetEventFF_EvtMCU_E_GPT12_CLC_DISABLE_ERR: start-on-event=RE_GetEventFreezeFrameData, operation=EvtInfo_MCU_E_GPT12_CLC_DISABLE_ERR.GetEventFreezeFrameData
        EV_GetEventEDR_EvtMCU_E_GPT12_CLC_DISABLE_ERR: start-on-event=RE_GetEventExtendedDataRecord, operation=EvtInfo_MCU_E_GPT12_CLC_DISABLE_ERR.GetEventExtendedDataRecord
        EV_GetEventStatus_EvtMCU_E_PMSWCR_UPDATE_ERR: start-on-event=RE_GetEventStatus, operation=EvtInfo_MCU_E_PMSWCR_UPDATE_ERR.GetEventStatus
        EV_GetEventFailed_EvtMCU_E_PMSWCR_UPDATE_ERR: start-on-event=RE_GetEventFailed, operation=EvtInfo_MCU_E_PMSWCR_UPDATE_ERR.GetEventFailed
        EV_GetEventTested_EvtMCU_E_PMSWCR_UPDATE_ERR: start-on-event=RE_GetEventTested, operation=EvtInfo_MCU_E_PMSWCR_UPDATE_ERR.GetEventTested
        EV_GetDTCOfEvent_EvtMCU_E_PMSWCR_UPDATE_ERR: start-on-event=RE_GetDTCOfEvent, operation=EvtInfo_MCU_E_PMSWCR_UPDATE_ERR.GetDTCOfEvent
        EV_GetFDC_EvtMCU_E_PMSWCR_UPDATE_ERR: start-on-event=RE_GetFaultDetectionCounter, operation=EvtInfo_MCU_E_PMSWCR_UPDATE_ERR.GetFaultDetectionCounter
        EV_GetEventFF_EvtMCU_E_PMSWCR_UPDATE_ERR: start-on-event=RE_GetEventFreezeFrameData, operation=EvtInfo_MCU_E_PMSWCR_UPDATE_ERR.GetEventFreezeFrameData
        EV_GetEventEDR_EvtMCU_E_PMSWCR_UPDATE_ERR: start-on-event=RE_GetEventExtendedDataRecord, operation=EvtInfo_MCU_E_PMSWCR_UPDATE_ERR.GetEventExtendedDataRecord
        EV_GetEventStatus_EvtCANSM_BUSOFF_PublicCAN: start-on-event=RE_GetEventStatus, operation=EvtInfo_CANSM_BUSOFF_PublicCAN.GetEventStatus
        EV_GetEventFailed_EvtCANSM_BUSOFF_PublicCAN: start-on-event=RE_GetEventFailed, operation=EvtInfo_CANSM_BUSOFF_PublicCAN.GetEventFailed
        EV_GetEventTested_EvtCANSM_BUSOFF_PublicCAN: start-on-event=RE_GetEventTested, operation=EvtInfo_CANSM_BUSOFF_PublicCAN.GetEventTested
        EV_GetDTCOfEvent_EvtCANSM_BUSOFF_PublicCAN: start-on-event=RE_GetDTCOfEvent, operation=EvtInfo_CANSM_BUSOFF_PublicCAN.GetDTCOfEvent
        EV_GetFDC_EvtCANSM_BUSOFF_PublicCAN: start-on-event=RE_GetFaultDetectionCounter, operation=EvtInfo_CANSM_BUSOFF_PublicCAN.GetFaultDetectionCounter
        EV_GetEventFF_EvtCANSM_BUSOFF_PublicCAN: start-on-event=RE_GetEventFreezeFrameData, operation=EvtInfo_CANSM_BUSOFF_PublicCAN.GetEventFreezeFrameData
        EV_GetEventEDR_EvtCANSM_BUSOFF_PublicCAN: start-on-event=RE_GetEventExtendedDataRecord, operation=EvtInfo_CANSM_BUSOFF_PublicCAN.GetEventExtendedDataRecord
        EV_GetEventStatus_EvtSPI_E_HARDWARE_ERROR: start-on-event=RE_GetEventStatus, operation=EvtInfo_SPI_E_HARDWARE_ERROR.GetEventStatus
        EV_GetEventFailed_EvtSPI_E_HARDWARE_ERROR: start-on-event=RE_GetEventFailed, operation=EvtInfo_SPI_E_HARDWARE_ERROR.GetEventFailed
        EV_GetEventTested_EvtSPI_E_HARDWARE_ERROR: start-on-event=RE_GetEventTested, operation=EvtInfo_SPI_E_HARDWARE_ERROR.GetEventTested
        EV_GetDTCOfEvent_EvtSPI_E_HARDWARE_ERROR: start-on-event=RE_GetDTCOfEvent, operation=EvtInfo_SPI_E_HARDWARE_ERROR.GetDTCOfEvent
        EV_GetFDC_EvtSPI_E_HARDWARE_ERROR: start-on-event=RE_GetFaultDetectionCounter, operation=EvtInfo_SPI_E_HARDWARE_ERROR.GetFaultDetectionCounter
        EV_GetEventFF_EvtSPI_E_HARDWARE_ERROR: start-on-event=RE_GetEventFreezeFrameData, operation=EvtInfo_SPI_E_HARDWARE_ERROR.GetEventFreezeFrameData
        EV_GetEventEDR_EvtSPI_E_HARDWARE_ERROR: start-on-event=RE_GetEventExtendedDataRecord, operation=EvtInfo_SPI_E_HARDWARE_ERROR.GetEventExtendedDataRecord
        EV_SetEventStatus_EvtDEM_VMON_BATT_HIGH: start-on-event=RE_SetEventStatus, operation=Event_DEM_VMON_BATT_HIGH.SetEventStatus
        EV_ResetEventStatus_EvtDEM_VMON_BATT_HIGH: start-on-event=RE_ResetEventStatus, operation=Event_DEM_VMON_BATT_HIGH.ResetEventStatus
        EV_PrestoreFreezeFrame_EvtDEM_VMON_BATT_HIGH: start-on-event=RE_PrestoreFreezeFrame, operation=Event_DEM_VMON_BATT_HIGH.PrestoreFreezeFrame
        EV_ClearPrestoredFF_EvtDEM_VMON_BATT_HIGH: start-on-event=RE_ClearPrestoredFreezeFrame, operation=Event_DEM_VMON_BATT_HIGH.ClearPrestoredFreezeFrame
        EV_ResetEventDebounceStatus_EvtDEM_VMON_BATT_HIGH: start-on-event=RE_ResetEventDebounceStatus, operation=Event_DEM_VMON_BATT_HIGH.ResetEventDebounceStatus
        EV_GetEventStatus_EvtDEM_VMON_BATT_HIGH: start-on-event=RE_GetEventStatus, operation=EvtInfo_DEM_VMON_BATT_HIGH.GetEventStatus
        EV_GetEventFailed_EvtDEM_VMON_BATT_HIGH: start-on-event=RE_GetEventFailed, operation=EvtInfo_DEM_VMON_BATT_HIGH.GetEventFailed
        EV_GetEventTested_EvtDEM_VMON_BATT_HIGH: start-on-event=RE_GetEventTested, operation=EvtInfo_DEM_VMON_BATT_HIGH.GetEventTested
        EV_GetDTCOfEvent_EvtDEM_VMON_BATT_HIGH: start-on-event=RE_GetDTCOfEvent, operation=EvtInfo_DEM_VMON_BATT_HIGH.GetDTCOfEvent
        EV_GetFDC_EvtDEM_VMON_BATT_HIGH: start-on-event=RE_GetFaultDetectionCounter, operation=EvtInfo_DEM_VMON_BATT_HIGH.GetFaultDetectionCounter
        EV_GetEventFF_EvtDEM_VMON_BATT_HIGH: start-on-event=RE_GetEventFreezeFrameData, operation=EvtInfo_DEM_VMON_BATT_HIGH.GetEventFreezeFrameData
        EV_GetEventEDR_EvtDEM_VMON_BATT_HIGH: start-on-event=RE_GetEventExtendedDataRecord, operation=EvtInfo_DEM_VMON_BATT_HIGH.GetEventExtendedDataRecord
        EV_SetEventStatus_EvtDEM_VMON_BATT_LOW: start-on-event=RE_SetEventStatus, operation=Event_DEM_VMON_BATT_LOW.SetEventStatus
        EV_ResetEventStatus_EvtDEM_VMON_BATT_LOW: start-on-event=RE_ResetEventStatus, operation=Event_DEM_VMON_BATT_LOW.ResetEventStatus
        EV_PrestoreFreezeFrame_EvtDEM_VMON_BATT_LOW: start-on-event=RE_PrestoreFreezeFrame, operation=Event_DEM_VMON_BATT_LOW.PrestoreFreezeFrame
        EV_ClearPrestoredFF_EvtDEM_VMON_BATT_LOW: start-on-event=RE_ClearPrestoredFreezeFrame, operation=Event_DEM_VMON_BATT_LOW.ClearPrestoredFreezeFrame
        EV_ResetEventDebounceStatus_EvtDEM_VMON_BATT_LOW: start-on-event=RE_ResetEventDebounceStatus, operation=Event_DEM_VMON_BATT_LOW.ResetEventDebounceStatus
        EV_GetEventStatus_EvtDEM_VMON_BATT_LOW: start-on-event=RE_GetEventStatus, operation=EvtInfo_DEM_VMON_BATT_LOW.GetEventStatus
        EV_GetEventFailed_EvtDEM_VMON_BATT_LOW: start-on-event=RE_GetEventFailed, operation=EvtInfo_DEM_VMON_BATT_LOW.GetEventFailed
        EV_GetEventTested_EvtDEM_VMON_BATT_LOW: start-on-event=RE_GetEventTested, operation=EvtInfo_DEM_VMON_BATT_LOW.GetEventTested
        EV_GetDTCOfEvent_EvtDEM_VMON_BATT_LOW: start-on-event=RE_GetDTCOfEvent, operation=EvtInfo_DEM_VMON_BATT_LOW.GetDTCOfEvent
        EV_GetFDC_EvtDEM_VMON_BATT_LOW: start-on-event=RE_GetFaultDetectionCounter, operation=EvtInfo_DEM_VMON_BATT_LOW.GetFaultDetectionCounter
        EV_GetEventFF_EvtDEM_VMON_BATT_LOW: start-on-event=RE_GetEventFreezeFrameData, operation=EvtInfo_DEM_VMON_BATT_LOW.GetEventFreezeFrameData
        EV_GetEventEDR_EvtDEM_VMON_BATT_LOW: start-on-event=RE_GetEventExtendedDataRecord, operation=EvtInfo_DEM_VMON_BATT_LOW.GetEventExtendedDataRecord
        EV_SetEventStatus_EvtDEM_MCU_TEMP_EXT_HIGH: start-on-event=RE_SetEventStatus, operation=Event_DEM_MCU_TEMP_EXT_HIGH.SetEventStatus
        EV_ResetEventStatus_EvtDEM_MCU_TEMP_EXT_HIGH: start-on-event=RE_ResetEventStatus, operation=Event_DEM_MCU_TEMP_EXT_HIGH.ResetEventStatus
        EV_PrestoreFreezeFrame_EvtDEM_MCU_TEMP_EXT_HIGH: start-on-event=RE_PrestoreFreezeFrame, operation=Event_DEM_MCU_TEMP_EXT_HIGH.PrestoreFreezeFrame
        EV_ClearPrestoredFF_EvtDEM_MCU_TEMP_EXT_HIGH: start-on-event=RE_ClearPrestoredFreezeFrame, operation=Event_DEM_MCU_TEMP_EXT_HIGH.ClearPrestoredFreezeFrame
        EV_ResetEventDebounceStatus_EvtDEM_MCU_TEMP_EXT_HIGH: start-on-event=RE_ResetEventDebounceStatus, operation=Event_DEM_MCU_TEMP_EXT_HIGH.ResetEventDebounceStatus
        EV_GetEventStatus_EvtDEM_MCU_TEMP_EXT_HIGH: start-on-event=RE_GetEventStatus, operation=EvtInfo_DEM_MCU_TEMP_EXT_HIGH.GetEventStatus
        EV_GetEventFailed_EvtDEM_MCU_TEMP_EXT_HIGH: start-on-event=RE_GetEventFailed, operation=EvtInfo_DEM_MCU_TEMP_EXT_HIGH.GetEventFailed
        EV_GetEventTested_EvtDEM_MCU_TEMP_EXT_HIGH: start-on-event=RE_GetEventTested, operation=EvtInfo_DEM_MCU_TEMP_EXT_HIGH.GetEventTested
        EV_GetDTCOfEvent_EvtDEM_MCU_TEMP_EXT_HIGH: start-on-event=RE_GetDTCOfEvent, operation=EvtInfo_DEM_MCU_TEMP_EXT_HIGH.GetDTCOfEvent
        EV_GetFDC_EvtDEM_MCU_TEMP_EXT_HIGH: start-on-event=RE_GetFaultDetectionCounter, operation=EvtInfo_DEM_MCU_TEMP_EXT_HIGH.GetFaultDetectionCounter
        EV_GetEventFF_EvtDEM_MCU_TEMP_EXT_HIGH: start-on-event=RE_GetEventFreezeFrameData, operation=EvtInfo_DEM_MCU_TEMP_EXT_HIGH.GetEventFreezeFrameData
        EV_GetEventEDR_EvtDEM_MCU_TEMP_EXT_HIGH: start-on-event=RE_GetEventExtendedDataRecord, operation=EvtInfo_DEM_MCU_TEMP_EXT_HIGH.GetEventExtendedDataRecord
        EV_SetEventStatus_EvtDEM_MCU_TEMP_EXT_LOW: start-on-event=RE_SetEventStatus, operation=Event_DEM_MCU_TEMP_EXT_LOW.SetEventStatus
        EV_ResetEventStatus_EvtDEM_MCU_TEMP_EXT_LOW: start-on-event=RE_ResetEventStatus, operation=Event_DEM_MCU_TEMP_EXT_LOW.ResetEventStatus
        EV_PrestoreFreezeFrame_EvtDEM_MCU_TEMP_EXT_LOW: start-on-event=RE_PrestoreFreezeFrame, operation=Event_DEM_MCU_TEMP_EXT_LOW.PrestoreFreezeFrame
        EV_ClearPrestoredFF_EvtDEM_MCU_TEMP_EXT_LOW: start-on-event=RE_ClearPrestoredFreezeFrame, operation=Event_DEM_MCU_TEMP_EXT_LOW.ClearPrestoredFreezeFrame
        EV_ResetEventDebounceStatus_EvtDEM_MCU_TEMP_EXT_LOW: start-on-event=RE_ResetEventDebounceStatus, operation=Event_DEM_MCU_TEMP_EXT_LOW.ResetEventDebounceStatus
        EV_GetEventStatus_EvtDEM_MCU_TEMP_EXT_LOW: start-on-event=RE_GetEventStatus, operation=EvtInfo_DEM_MCU_TEMP_EXT_LOW.GetEventStatus
        EV_GetEventFailed_EvtDEM_MCU_TEMP_EXT_LOW: start-on-event=RE_GetEventFailed, operation=EvtInfo_DEM_MCU_TEMP_EXT_LOW.GetEventFailed
        EV_GetEventTested_EvtDEM_MCU_TEMP_EXT_LOW: start-on-event=RE_GetEventTested, operation=EvtInfo_DEM_MCU_TEMP_EXT_LOW.GetEventTested
        EV_GetDTCOfEvent_EvtDEM_MCU_TEMP_EXT_LOW: start-on-event=RE_GetDTCOfEvent, operation=EvtInfo_DEM_MCU_TEMP_EXT_LOW.GetDTCOfEvent
        EV_GetFDC_EvtDEM_MCU_TEMP_EXT_LOW: start-on-event=RE_GetFaultDetectionCounter, operation=EvtInfo_DEM_MCU_TEMP_EXT_LOW.GetFaultDetectionCounter
        EV_GetEventFF_EvtDEM_MCU_TEMP_EXT_LOW: start-on-event=RE_GetEventFreezeFrameData, operation=EvtInfo_DEM_MCU_TEMP_EXT_LOW.GetEventFreezeFrameData
        EV_GetEventEDR_EvtDEM_MCU_TEMP_EXT_LOW: start-on-event=RE_GetEventExtendedDataRecord, operation=EvtInfo_DEM_MCU_TEMP_EXT_LOW.GetEventExtendedDataRecord
        EV_SetEventStatus_EvtDEM_SOCJ3_TEMP_EXT_HIGH: start-on-event=RE_SetEventStatus, operation=Event_DEM_SOCJ3_TEMP_EXT_HIGH.SetEventStatus
        EV_ResetEventStatus_EvtDEM_SOCJ3_TEMP_EXT_HIGH: start-on-event=RE_ResetEventStatus, operation=Event_DEM_SOCJ3_TEMP_EXT_HIGH.ResetEventStatus
        EV_PrestoreFreezeFrame_EvtDEM_SOCJ3_TEMP_EXT_HIGH: start-on-event=RE_PrestoreFreezeFrame, operation=Event_DEM_SOCJ3_TEMP_EXT_HIGH.PrestoreFreezeFrame
        EV_ClearPrestoredFF_EvtDEM_SOCJ3_TEMP_EXT_HIGH: start-on-event=RE_ClearPrestoredFreezeFrame, operation=Event_DEM_SOCJ3_TEMP_EXT_HIGH.ClearPrestoredFreezeFrame
        EV_ResetEventDebounceStatus_EvtDEM_SOCJ3_TEMP_EXT_HIGH: start-on-event=RE_ResetEventDebounceStatus, operation=Event_DEM_SOCJ3_TEMP_EXT_HIGH.ResetEventDebounceStatus
        EV_GetEventStatus_EvtDEM_SOCJ3_TEMP_EXT_HIGH: start-on-event=RE_GetEventStatus, operation=EvtInfo_DEM_SOCJ3_TEMP_EXT_HIGH.GetEventStatus
        EV_GetEventFailed_EvtDEM_SOCJ3_TEMP_EXT_HIGH: start-on-event=RE_GetEventFailed, operation=EvtInfo_DEM_SOCJ3_TEMP_EXT_HIGH.GetEventFailed
        EV_GetEventTested_EvtDEM_SOCJ3_TEMP_EXT_HIGH: start-on-event=RE_GetEventTested, operation=EvtInfo_DEM_SOCJ3_TEMP_EXT_HIGH.GetEventTested
        EV_GetDTCOfEvent_EvtDEM_SOCJ3_TEMP_EXT_HIGH: start-on-event=RE_GetDTCOfEvent, operation=EvtInfo_DEM_SOCJ3_TEMP_EXT_HIGH.GetDTCOfEvent
        EV_GetFDC_EvtDEM_SOCJ3_TEMP_EXT_HIGH: start-on-event=RE_GetFaultDetectionCounter, operation=EvtInfo_DEM_SOCJ3_TEMP_EXT_HIGH.GetFaultDetectionCounter
        EV_GetEventFF_EvtDEM_SOCJ3_TEMP_EXT_HIGH: start-on-event=RE_GetEventFreezeFrameData, operation=EvtInfo_DEM_SOCJ3_TEMP_EXT_HIGH.GetEventFreezeFrameData
        EV_GetEventEDR_EvtDEM_SOCJ3_TEMP_EXT_HIGH: start-on-event=RE_GetEventExtendedDataRecord, operation=EvtInfo_DEM_SOCJ3_TEMP_EXT_HIGH.GetEventExtendedDataRecord
        EV_SetEventStatus_EvtDEM_J3_SYS_KERNEL_SW: start-on-event=RE_SetEventStatus, operation=Event_DEM_J3_SYS_KERNEL_SW.SetEventStatus
        EV_ResetEventStatus_EvtDEM_J3_SYS_KERNEL_SW: start-on-event=RE_ResetEventStatus, operation=Event_DEM_J3_SYS_KERNEL_SW.ResetEventStatus
        EV_PrestoreFreezeFrame_EvtDEM_J3_SYS_KERNEL_SW: start-on-event=RE_PrestoreFreezeFrame, operation=Event_DEM_J3_SYS_KERNEL_SW.PrestoreFreezeFrame
        EV_ClearPrestoredFF_EvtDEM_J3_SYS_KERNEL_SW: start-on-event=RE_ClearPrestoredFreezeFrame, operation=Event_DEM_J3_SYS_KERNEL_SW.ClearPrestoredFreezeFrame
        EV_ResetEventDebounceStatus_EvtDEM_J3_SYS_KERNEL_SW: start-on-event=RE_ResetEventDebounceStatus, operation=Event_DEM_J3_SYS_KERNEL_SW.ResetEventDebounceStatus
        EV_GetEventStatus_EvtDEM_J3_SYS_KERNEL_SW: start-on-event=RE_GetEventStatus, operation=EvtInfo_DEM_J3_SYS_KERNEL_SW.GetEventStatus
        EV_GetEventFailed_EvtDEM_J3_SYS_KERNEL_SW: start-on-event=RE_GetEventFailed, operation=EvtInfo_DEM_J3_SYS_KERNEL_SW.GetEventFailed
        EV_GetEventTested_EvtDEM_J3_SYS_KERNEL_SW: start-on-event=RE_GetEventTested, operation=EvtInfo_DEM_J3_SYS_KERNEL_SW.GetEventTested
        EV_GetDTCOfEvent_EvtDEM_J3_SYS_KERNEL_SW: start-on-event=RE_GetDTCOfEvent, operation=EvtInfo_DEM_J3_SYS_KERNEL_SW.GetDTCOfEvent
        EV_GetFDC_EvtDEM_J3_SYS_KERNEL_SW: start-on-event=RE_GetFaultDetectionCounter, operation=EvtInfo_DEM_J3_SYS_KERNEL_SW.GetFaultDetectionCounter
        EV_GetEventFF_EvtDEM_J3_SYS_KERNEL_SW: start-on-event=RE_GetEventFreezeFrameData, operation=EvtInfo_DEM_J3_SYS_KERNEL_SW.GetEventFreezeFrameData
        EV_GetEventEDR_EvtDEM_J3_SYS_KERNEL_SW: start-on-event=RE_GetEventExtendedDataRecord, operation=EvtInfo_DEM_J3_SYS_KERNEL_SW.GetEventExtendedDataRecord
        EV_GetEventStatus_EvtAdcClcFailureNotification: start-on-event=RE_GetEventStatus, operation=EvtInfo_AdcClcFailureNotification.GetEventStatus
        EV_GetEventFailed_EvtAdcClcFailureNotification: start-on-event=RE_GetEventFailed, operation=EvtInfo_AdcClcFailureNotification.GetEventFailed
        EV_GetEventTested_EvtAdcClcFailureNotification: start-on-event=RE_GetEventTested, operation=EvtInfo_AdcClcFailureNotification.GetEventTested
        EV_GetDTCOfEvent_EvtAdcClcFailureNotification: start-on-event=RE_GetDTCOfEvent, operation=EvtInfo_AdcClcFailureNotification.GetDTCOfEvent
        EV_GetFDC_EvtAdcClcFailureNotification: start-on-event=RE_GetFaultDetectionCounter, operation=EvtInfo_AdcClcFailureNotification.GetFaultDetectionCounter
        EV_GetEventFF_EvtAdcClcFailureNotification: start-on-event=RE_GetEventFreezeFrameData, operation=EvtInfo_AdcClcFailureNotification.GetEventFreezeFrameData
        EV_GetEventEDR_EvtAdcClcFailureNotification: start-on-event=RE_GetEventExtendedDataRecord, operation=EvtInfo_AdcClcFailureNotification.GetEventExtendedDataRecord
        EV_GetEventStatus_EvtAdcConvStopTimeNotification: start-on-event=RE_GetEventStatus, operation=EvtInfo_AdcConvStopTimeNotification.GetEventStatus
        EV_GetEventFailed_EvtAdcConvStopTimeNotification: start-on-event=RE_GetEventFailed, operation=EvtInfo_AdcConvStopTimeNotification.GetEventFailed
        EV_GetEventTested_EvtAdcConvStopTimeNotification: start-on-event=RE_GetEventTested, operation=EvtInfo_AdcConvStopTimeNotification.GetEventTested
        EV_GetDTCOfEvent_EvtAdcConvStopTimeNotification: start-on-event=RE_GetDTCOfEvent, operation=EvtInfo_AdcConvStopTimeNotification.GetDTCOfEvent
        EV_GetFDC_EvtAdcConvStopTimeNotification: start-on-event=RE_GetFaultDetectionCounter, operation=EvtInfo_AdcConvStopTimeNotification.GetFaultDetectionCounter
        EV_GetEventFF_EvtAdcConvStopTimeNotification: start-on-event=RE_GetEventFreezeFrameData, operation=EvtInfo_AdcConvStopTimeNotification.GetEventFreezeFrameData
        EV_GetEventEDR_EvtAdcConvStopTimeNotification: start-on-event=RE_GetEventExtendedDataRecord, operation=EvtInfo_AdcConvStopTimeNotification.GetEventExtendedDataRecord
        EV_GetEventStatus_EvtFEE_E_GC_INIT: start-on-event=RE_GetEventStatus, operation=EvtInfo_FEE_E_GC_INIT.GetEventStatus
        EV_GetEventFailed_EvtFEE_E_GC_INIT: start-on-event=RE_GetEventFailed, operation=EvtInfo_FEE_E_GC_INIT.GetEventFailed
        EV_GetEventTested_EvtFEE_E_GC_INIT: start-on-event=RE_GetEventTested, operation=EvtInfo_FEE_E_GC_INIT.GetEventTested
        EV_GetDTCOfEvent_EvtFEE_E_GC_INIT: start-on-event=RE_GetDTCOfEvent, operation=EvtInfo_FEE_E_GC_INIT.GetDTCOfEvent
        EV_GetFDC_EvtFEE_E_GC_INIT: start-on-event=RE_GetFaultDetectionCounter, operation=EvtInfo_FEE_E_GC_INIT.GetFaultDetectionCounter
        EV_GetEventFF_EvtFEE_E_GC_INIT: start-on-event=RE_GetEventFreezeFrameData, operation=EvtInfo_FEE_E_GC_INIT.GetEventFreezeFrameData
        EV_GetEventEDR_EvtFEE_E_GC_INIT: start-on-event=RE_GetEventExtendedDataRecord, operation=EvtInfo_FEE_E_GC_INIT.GetEventExtendedDataRecord
        EV_GetEventStatus_EvtFEE_E_WRITE: start-on-event=RE_GetEventStatus, operation=EvtInfo_FEE_E_WRITE.GetEventStatus
        EV_GetEventFailed_EvtFEE_E_WRITE: start-on-event=RE_GetEventFailed, operation=EvtInfo_FEE_E_WRITE.GetEventFailed
        EV_GetEventTested_EvtFEE_E_WRITE: start-on-event=RE_GetEventTested, operation=EvtInfo_FEE_E_WRITE.GetEventTested
        EV_GetDTCOfEvent_EvtFEE_E_WRITE: start-on-event=RE_GetDTCOfEvent, operation=EvtInfo_FEE_E_WRITE.GetDTCOfEvent
        EV_GetFDC_EvtFEE_E_WRITE: start-on-event=RE_GetFaultDetectionCounter, operation=EvtInfo_FEE_E_WRITE.GetFaultDetectionCounter
        EV_GetEventFF_EvtFEE_E_WRITE: start-on-event=RE_GetEventFreezeFrameData, operation=EvtInfo_FEE_E_WRITE.GetEventFreezeFrameData
        EV_GetEventEDR_EvtFEE_E_WRITE: start-on-event=RE_GetEventExtendedDataRecord, operation=EvtInfo_FEE_E_WRITE.GetEventExtendedDataRecord
        EV_GetEventStatus_EvtFEE_E_READ: start-on-event=RE_GetEventStatus, operation=EvtInfo_FEE_E_READ.GetEventStatus
        EV_GetEventFailed_EvtFEE_E_READ: start-on-event=RE_GetEventFailed, operation=EvtInfo_FEE_E_READ.GetEventFailed
        EV_GetEventTested_EvtFEE_E_READ: start-on-event=RE_GetEventTested, operation=EvtInfo_FEE_E_READ.GetEventTested
        EV_GetDTCOfEvent_EvtFEE_E_READ: start-on-event=RE_GetDTCOfEvent, operation=EvtInfo_FEE_E_READ.GetDTCOfEvent
        EV_GetFDC_EvtFEE_E_READ: start-on-event=RE_GetFaultDetectionCounter, operation=EvtInfo_FEE_E_READ.GetFaultDetectionCounter
        EV_GetEventFF_EvtFEE_E_READ: start-on-event=RE_GetEventFreezeFrameData, operation=EvtInfo_FEE_E_READ.GetEventFreezeFrameData
        EV_GetEventEDR_EvtFEE_E_READ: start-on-event=RE_GetEventExtendedDataRecord, operation=EvtInfo_FEE_E_READ.GetEventExtendedDataRecord
        EV_GetEventStatus_EvtFEE_E_GC_READ: start-on-event=RE_GetEventStatus, operation=EvtInfo_FEE_E_GC_READ.GetEventStatus
        EV_GetEventFailed_EvtFEE_E_GC_READ: start-on-event=RE_GetEventFailed, operation=EvtInfo_FEE_E_GC_READ.GetEventFailed
        EV_GetEventTested_EvtFEE_E_GC_READ: start-on-event=RE_GetEventTested, operation=EvtInfo_FEE_E_GC_READ.GetEventTested
        EV_GetDTCOfEvent_EvtFEE_E_GC_READ: start-on-event=RE_GetDTCOfEvent, operation=EvtInfo_FEE_E_GC_READ.GetDTCOfEvent
        EV_GetFDC_EvtFEE_E_GC_READ: start-on-event=RE_GetFaultDetectionCounter, operation=EvtInfo_FEE_E_GC_READ.GetFaultDetectionCounter
        EV_GetEventFF_EvtFEE_E_GC_READ: start-on-event=RE_GetEventFreezeFrameData, operation=EvtInfo_FEE_E_GC_READ.GetEventFreezeFrameData
        EV_GetEventEDR_EvtFEE_E_GC_READ: start-on-event=RE_GetEventExtendedDataRecord, operation=EvtInfo_FEE_E_GC_READ.GetEventExtendedDataRecord
        EV_GetEventStatus_EvtFEE_E_GC_WRITE: start-on-event=RE_GetEventStatus, operation=EvtInfo_FEE_E_GC_WRITE.GetEventStatus
        EV_GetEventFailed_EvtFEE_E_GC_WRITE: start-on-event=RE_GetEventFailed, operation=EvtInfo_FEE_E_GC_WRITE.GetEventFailed
        EV_GetEventTested_EvtFEE_E_GC_WRITE: start-on-event=RE_GetEventTested, operation=EvtInfo_FEE_E_GC_WRITE.GetEventTested
        EV_GetDTCOfEvent_EvtFEE_E_GC_WRITE: start-on-event=RE_GetDTCOfEvent, operation=EvtInfo_FEE_E_GC_WRITE.GetDTCOfEvent
        EV_GetFDC_EvtFEE_E_GC_WRITE: start-on-event=RE_GetFaultDetectionCounter, operation=EvtInfo_FEE_E_GC_WRITE.GetFaultDetectionCounter
        EV_GetEventFF_EvtFEE_E_GC_WRITE: start-on-event=RE_GetEventFreezeFrameData, operation=EvtInfo_FEE_E_GC_WRITE.GetEventFreezeFrameData
        EV_GetEventEDR_EvtFEE_E_GC_WRITE: start-on-event=RE_GetEventExtendedDataRecord, operation=EvtInfo_FEE_E_GC_WRITE.GetEventExtendedDataRecord
        EV_GetEventStatus_EvtFEE_E_GC_ERASE: start-on-event=RE_GetEventStatus, operation=EvtInfo_FEE_E_GC_ERASE.GetEventStatus
        EV_GetEventFailed_EvtFEE_E_GC_ERASE: start-on-event=RE_GetEventFailed, operation=EvtInfo_FEE_E_GC_ERASE.GetEventFailed
        EV_GetEventTested_EvtFEE_E_GC_ERASE: start-on-event=RE_GetEventTested, operation=EvtInfo_FEE_E_GC_ERASE.GetEventTested
        EV_GetDTCOfEvent_EvtFEE_E_GC_ERASE: start-on-event=RE_GetDTCOfEvent, operation=EvtInfo_FEE_E_GC_ERASE.GetDTCOfEvent
        EV_GetFDC_EvtFEE_E_GC_ERASE: start-on-event=RE_GetFaultDetectionCounter, operation=EvtInfo_FEE_E_GC_ERASE.GetFaultDetectionCounter
        EV_GetEventFF_EvtFEE_E_GC_ERASE: start-on-event=RE_GetEventFreezeFrameData, operation=EvtInfo_FEE_E_GC_ERASE.GetEventFreezeFrameData
        EV_GetEventEDR_EvtFEE_E_GC_ERASE: start-on-event=RE_GetEventExtendedDataRecord, operation=EvtInfo_FEE_E_GC_ERASE.GetEventExtendedDataRecord
        EV_GetEventStatus_EvtFEE_E_INVALIDATE: start-on-event=RE_GetEventStatus, operation=EvtInfo_FEE_E_INVALIDATE.GetEventStatus
        EV_GetEventFailed_EvtFEE_E_INVALIDATE: start-on-event=RE_GetEventFailed, operation=EvtInfo_FEE_E_INVALIDATE.GetEventFailed
        EV_GetEventTested_EvtFEE_E_INVALIDATE: start-on-event=RE_GetEventTested, operation=EvtInfo_FEE_E_INVALIDATE.GetEventTested
        EV_GetDTCOfEvent_EvtFEE_E_INVALIDATE: start-on-event=RE_GetDTCOfEvent, operation=EvtInfo_FEE_E_INVALIDATE.GetDTCOfEvent
        EV_GetFDC_EvtFEE_E_INVALIDATE: start-on-event=RE_GetFaultDetectionCounter, operation=EvtInfo_FEE_E_INVALIDATE.GetFaultDetectionCounter
        EV_GetEventFF_EvtFEE_E_INVALIDATE: start-on-event=RE_GetEventFreezeFrameData, operation=EvtInfo_FEE_E_INVALIDATE.GetEventFreezeFrameData
        EV_GetEventEDR_EvtFEE_E_INVALIDATE: start-on-event=RE_GetEventExtendedDataRecord, operation=EvtInfo_FEE_E_INVALIDATE.GetEventExtendedDataRecord
        EV_GetEventStatus_EvtFEE_E_WRITE_CYCLES_EXHAUSTED: start-on-event=RE_GetEventStatus, operation=EvtInfo_FEE_E_WRITE_CYCLES_EXHAUSTED.GetEventStatus
        EV_GetEventFailed_EvtFEE_E_WRITE_CYCLES_EXHAUSTED: start-on-event=RE_GetEventFailed, operation=EvtInfo_FEE_E_WRITE_CYCLES_EXHAUSTED.GetEventFailed
        EV_GetEventTested_EvtFEE_E_WRITE_CYCLES_EXHAUSTED: start-on-event=RE_GetEventTested, operation=EvtInfo_FEE_E_WRITE_CYCLES_EXHAUSTED.GetEventTested
        EV_GetDTCOfEvent_EvtFEE_E_WRITE_CYCLES_EXHAUSTED: start-on-event=RE_GetDTCOfEvent, operation=EvtInfo_FEE_E_WRITE_CYCLES_EXHAUSTED.GetDTCOfEvent
        EV_GetFDC_EvtFEE_E_WRITE_CYCLES_EXHAUSTED: start-on-event=RE_GetFaultDetectionCounter, operation=EvtInfo_FEE_E_WRITE_CYCLES_EXHAUSTED.GetFaultDetectionCounter
        EV_GetEventFF_EvtFEE_E_WRITE_CYCLES_EXHAUSTED: start-on-event=RE_GetEventFreezeFrameData, operation=EvtInfo_FEE_E_WRITE_CYCLES_EXHAUSTED.GetEventFreezeFrameData
        EV_GetEventEDR_EvtFEE_E_WRITE_CYCLES_EXHAUSTED: start-on-event=RE_GetEventExtendedDataRecord, operation=EvtInfo_FEE_E_WRITE_CYCLES_EXHAUSTED.GetEventExtendedDataRecord
        EV_GetEventStatus_EvtFEE_E_GC_TRIG: start-on-event=RE_GetEventStatus, operation=EvtInfo_FEE_E_GC_TRIG.GetEventStatus
        EV_GetEventFailed_EvtFEE_E_GC_TRIG: start-on-event=RE_GetEventFailed, operation=EvtInfo_FEE_E_GC_TRIG.GetEventFailed
        EV_GetEventTested_EvtFEE_E_GC_TRIG: start-on-event=RE_GetEventTested, operation=EvtInfo_FEE_E_GC_TRIG.GetEventTested
        EV_GetDTCOfEvent_EvtFEE_E_GC_TRIG: start-on-event=RE_GetDTCOfEvent, operation=EvtInfo_FEE_E_GC_TRIG.GetDTCOfEvent
        EV_GetFDC_EvtFEE_E_GC_TRIG: start-on-event=RE_GetFaultDetectionCounter, operation=EvtInfo_FEE_E_GC_TRIG.GetFaultDetectionCounter
        EV_GetEventFF_EvtFEE_E_GC_TRIG: start-on-event=RE_GetEventFreezeFrameData, operation=EvtInfo_FEE_E_GC_TRIG.GetEventFreezeFrameData
        EV_GetEventEDR_EvtFEE_E_GC_TRIG: start-on-event=RE_GetEventExtendedDataRecord, operation=EvtInfo_FEE_E_GC_TRIG.GetEventExtendedDataRecord
        EV_GetEventStatus_EvtFEE_E_UNCONFIG_BLK_EXCEEDED: start-on-event=RE_GetEventStatus, operation=EvtInfo_FEE_E_UNCONFIG_BLK_EXCEEDED.GetEventStatus
        EV_GetEventFailed_EvtFEE_E_UNCONFIG_BLK_EXCEEDED: start-on-event=RE_GetEventFailed, operation=EvtInfo_FEE_E_UNCONFIG_BLK_EXCEEDED.GetEventFailed
        EV_GetEventTested_EvtFEE_E_UNCONFIG_BLK_EXCEEDED: start-on-event=RE_GetEventTested, operation=EvtInfo_FEE_E_UNCONFIG_BLK_EXCEEDED.GetEventTested
        EV_GetDTCOfEvent_EvtFEE_E_UNCONFIG_BLK_EXCEEDED: start-on-event=RE_GetDTCOfEvent, operation=EvtInfo_FEE_E_UNCONFIG_BLK_EXCEEDED.GetDTCOfEvent
        EV_GetFDC_EvtFEE_E_UNCONFIG_BLK_EXCEEDED: start-on-event=RE_GetFaultDetectionCounter, operation=EvtInfo_FEE_E_UNCONFIG_BLK_EXCEEDED.GetFaultDetectionCounter
        EV_GetEventFF_EvtFEE_E_UNCONFIG_BLK_EXCEEDED: start-on-event=RE_GetEventFreezeFrameData, operation=EvtInfo_FEE_E_UNCONFIG_BLK_EXCEEDED.GetEventFreezeFrameData
        EV_GetEventEDR_EvtFEE_E_UNCONFIG_BLK_EXCEEDED: start-on-event=RE_GetEventExtendedDataRecord, operation=EvtInfo_FEE_E_UNCONFIG_BLK_EXCEEDED.GetEventExtendedDataRecord
        EV_GetEventStatus_EvtFLS_E_COMPARE_FAILED: start-on-event=RE_GetEventStatus, operation=EvtInfo_FLS_E_COMPARE_FAILED.GetEventStatus
        EV_GetEventFailed_EvtFLS_E_COMPARE_FAILED: start-on-event=RE_GetEventFailed, operation=EvtInfo_FLS_E_COMPARE_FAILED.GetEventFailed
        EV_GetEventTested_EvtFLS_E_COMPARE_FAILED: start-on-event=RE_GetEventTested, operation=EvtInfo_FLS_E_COMPARE_FAILED.GetEventTested
        EV_GetDTCOfEvent_EvtFLS_E_COMPARE_FAILED: start-on-event=RE_GetDTCOfEvent, operation=EvtInfo_FLS_E_COMPARE_FAILED.GetDTCOfEvent
        EV_GetFDC_EvtFLS_E_COMPARE_FAILED: start-on-event=RE_GetFaultDetectionCounter, operation=EvtInfo_FLS_E_COMPARE_FAILED.GetFaultDetectionCounter
        EV_GetEventFF_EvtFLS_E_COMPARE_FAILED: start-on-event=RE_GetEventFreezeFrameData, operation=EvtInfo_FLS_E_COMPARE_FAILED.GetEventFreezeFrameData
        EV_GetEventEDR_EvtFLS_E_COMPARE_FAILED: start-on-event=RE_GetEventExtendedDataRecord, operation=EvtInfo_FLS_E_COMPARE_FAILED.GetEventExtendedDataRecord
        EV_GetEventStatus_EvtFLS_E_ERASE_FAILED: start-on-event=RE_GetEventStatus, operation=EvtInfo_FLS_E_ERASE_FAILED.GetEventStatus
        EV_GetEventFailed_EvtFLS_E_ERASE_FAILED: start-on-event=RE_GetEventFailed, operation=EvtInfo_FLS_E_ERASE_FAILED.GetEventFailed
        EV_GetEventTested_EvtFLS_E_ERASE_FAILED: start-on-event=RE_GetEventTested, operation=EvtInfo_FLS_E_ERASE_FAILED.GetEventTested
